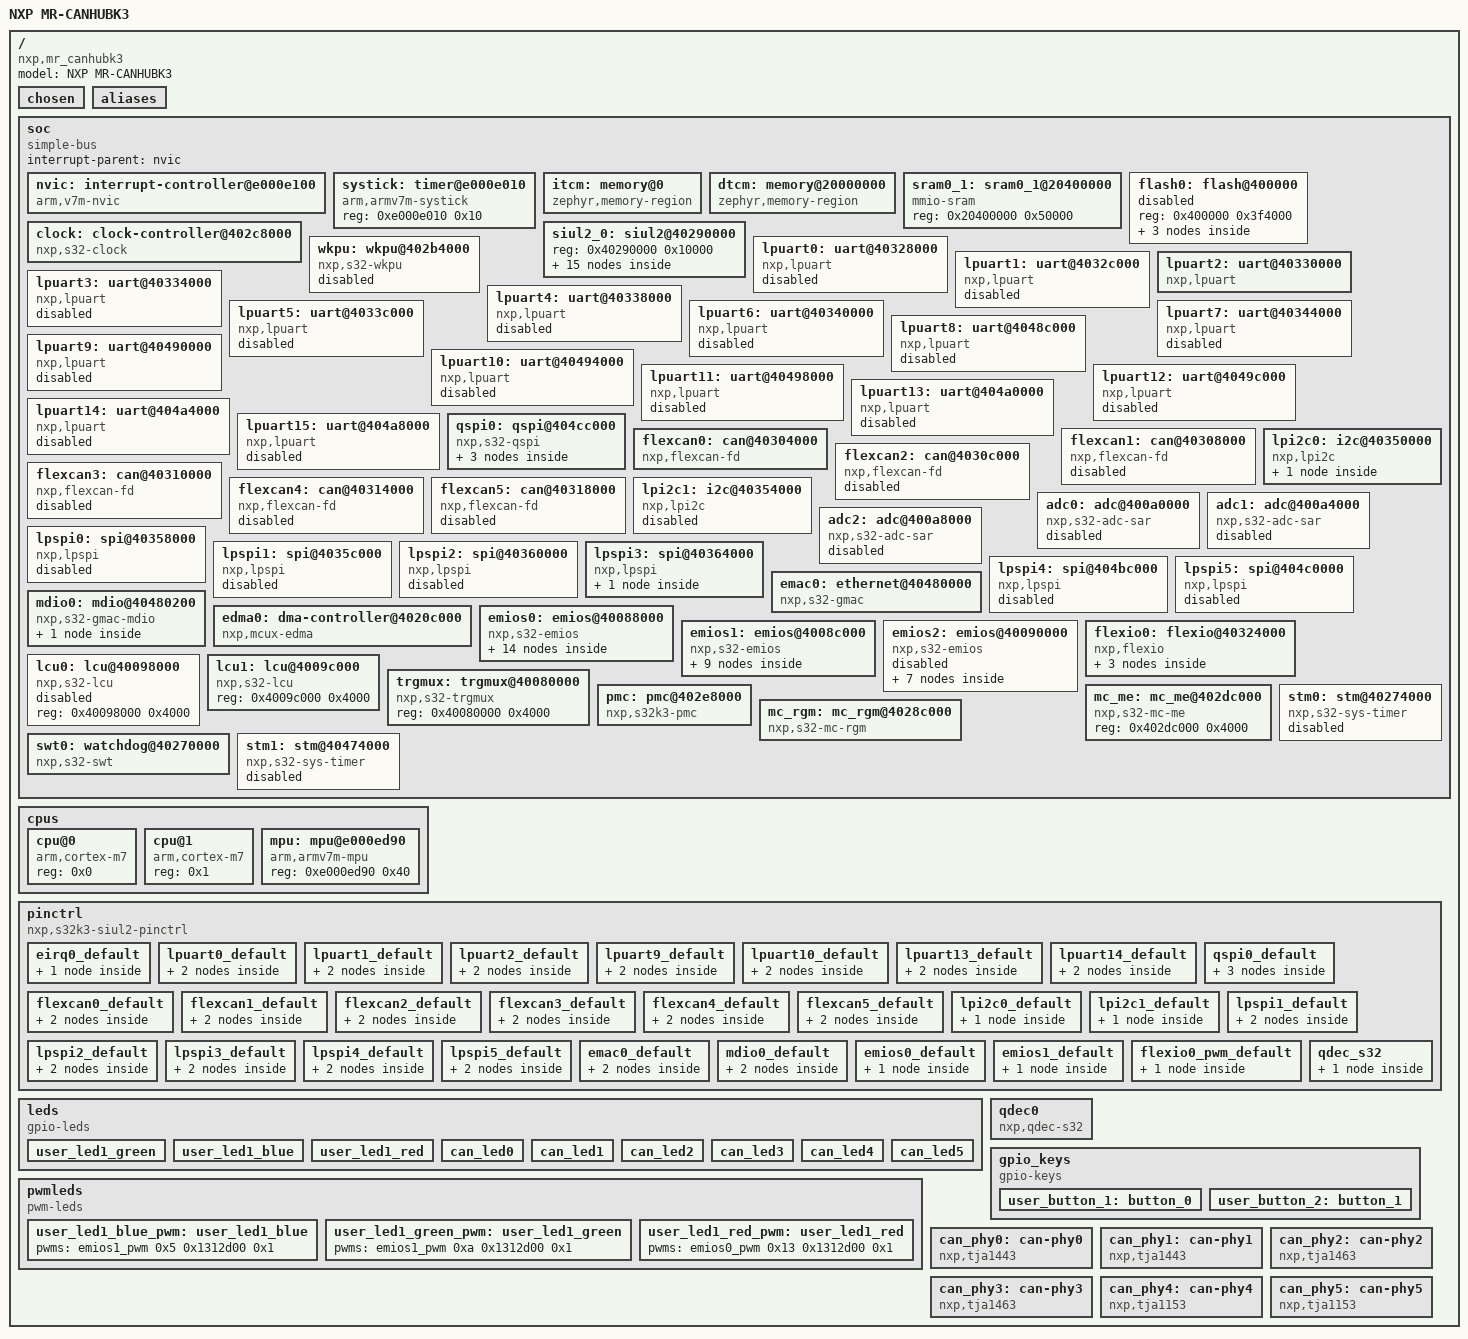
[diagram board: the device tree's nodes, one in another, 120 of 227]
/dts-v1/;

/* node '/' defined in zephyr/dts/common/skeleton.dtsi:9 */
/ {
	#address-cells = < 0x1 >;       /* in zephyr/dts/common/skeleton.dtsi:10 */
	#size-cells = < 0x1 >;          /* in zephyr/dts/common/skeleton.dtsi:11 */
	model = "NXP MR-CANHUBK3";      /* in zephyr/boards/nxp/mr_canhubk3/mr_canhubk3.dts:17 */
	compatible = "nxp,mr_canhubk3"; /* in zephyr/boards/nxp/mr_canhubk3/mr_canhubk3.dts:18 */

	/* node '/chosen' defined in zephyr/dts/common/skeleton.dtsi:13 */
	chosen {
		zephyr,sram = &sram0_1;                  /* in zephyr/boards/nxp/mr_canhubk3/mr_canhubk3.dts:21 */
		zephyr,flash = &flash0;                  /* in zephyr/boards/nxp/mr_canhubk3/mr_canhubk3.dts:22 */
		zephyr,itcm = &itcm;                     /* in zephyr/boards/nxp/mr_canhubk3/mr_canhubk3.dts:23 */
		zephyr,dtcm = &dtcm;                     /* in zephyr/boards/nxp/mr_canhubk3/mr_canhubk3.dts:24 */
		zephyr,code-partition = &code_partition; /* in zephyr/boards/nxp/mr_canhubk3/mr_canhubk3.dts:25 */
		zephyr,console = &lpuart2;               /* in zephyr/boards/nxp/mr_canhubk3/mr_canhubk3.dts:26 */
		zephyr,shell-uart = &lpuart2;            /* in zephyr/boards/nxp/mr_canhubk3/mr_canhubk3.dts:27 */
		zephyr,flash-controller = &mx25l6433f;   /* in zephyr/boards/nxp/mr_canhubk3/mr_canhubk3.dts:28 */
		zephyr,canbus = &flexcan0;               /* in zephyr/boards/nxp/mr_canhubk3/mr_canhubk3.dts:29 */
		zephyr,display = &ssd1306;               /* in zephyr/boards/nxp/mr_canhubk3/mr_canhubk3.dts:30 */
	};

	/* node '/aliases' defined in zephyr/dts/common/skeleton.dtsi:15 */
	aliases {
		dma0 = &edma0;                        /* in zephyr/boards/nxp/mr_canhubk3/mr_canhubk3.dts:34 */
		led0 = &user_led1_red;                /* in zephyr/boards/nxp/mr_canhubk3/mr_canhubk3.dts:35 */
		led1 = &user_led1_green;              /* in zephyr/boards/nxp/mr_canhubk3/mr_canhubk3.dts:36 */
		led2 = &user_led1_blue;               /* in zephyr/boards/nxp/mr_canhubk3/mr_canhubk3.dts:37 */
		sw0 = &user_button_1;                 /* in zephyr/boards/nxp/mr_canhubk3/mr_canhubk3.dts:38 */
		sw1 = &user_button_2;                 /* in zephyr/boards/nxp/mr_canhubk3/mr_canhubk3.dts:39 */
		watchdog0 = &swt0;                    /* in zephyr/boards/nxp/mr_canhubk3/mr_canhubk3.dts:40 */
		pwm-0 = &emios0_pwm;                  /* in zephyr/boards/nxp/mr_canhubk3/mr_canhubk3.dts:42 */
		pwm-1 = &flexio0_pwm;                 /* in zephyr/boards/nxp/mr_canhubk3/mr_canhubk3.dts:43 */
		red-pwm-led = &user_led1_red_pwm;     /* in zephyr/boards/nxp/mr_canhubk3/mr_canhubk3.dts:44 */
		green-pwm-led = &user_led1_green_pwm; /* in zephyr/boards/nxp/mr_canhubk3/mr_canhubk3.dts:45 */
		blue-pwm-led = &user_led1_blue_pwm;   /* in zephyr/boards/nxp/mr_canhubk3/mr_canhubk3.dts:46 */
		pwm-led0 = &user_led1_blue_pwm;       /* in zephyr/boards/nxp/mr_canhubk3/mr_canhubk3.dts:47 */
		qdec0 = &qdec0;                       /* in zephyr/boards/nxp/mr_canhubk3/mr_canhubk3.dts:48 */
	};

	/* node '/soc' defined in zephyr/dts/arm/armv7-m.dtsi:6 */
	soc {
		#address-cells = < 0x1 >;     /* in zephyr/dts/arm/armv7-m.dtsi:7 */
		#size-cells = < 0x1 >;        /* in zephyr/dts/arm/armv7-m.dtsi:8 */
		compatible = "simple-bus";    /* in zephyr/dts/arm/armv7-m.dtsi:9 */
		ranges;                       /* in zephyr/dts/arm/armv7-m.dtsi:11 */
		interrupt-parent = < &nvic >; /* in zephyr/dts/arm/nxp/nxp_s32k344_m7.dtsi:44 */

		/* node '/soc/interrupt-controller@e000e100' defined in zephyr/dts/arm/armv7-m.dtsi:13 */
		nvic: interrupt-controller@e000e100 {
			#address-cells = < 0x1 >;            /* in zephyr/dts/arm/armv7-m.dtsi:14 */
			compatible = "arm,v7m-nvic";         /* in zephyr/dts/arm/armv7-m.dtsi:15 */
			reg = < 0xe000e100 0xc00 >;          /* in zephyr/dts/arm/armv7-m.dtsi:16 */
			interrupt-controller;                /* in zephyr/dts/arm/armv7-m.dtsi:17 */
			#interrupt-cells = < 0x2 >;          /* in zephyr/dts/arm/armv7-m.dtsi:18 */
			arm,num-irq-priority-bits = < 0x4 >; /* in zephyr/dts/arm/nxp/nxp_s32k344_m7.dtsi:924 */
			phandle = < 0x1 >;                   /* in zephyr/dts/arm/nxp/nxp_s32k344_m7.dtsi:44 */
		};

		/* node '/soc/timer@e000e010' defined in zephyr/dts/arm/armv7-m.dtsi:21 */
		systick: timer@e000e010 {
			compatible = "arm,armv7m-systick"; /* in zephyr/dts/arm/armv7-m.dtsi:22 */
			reg = < 0xe000e010 0x10 >;         /* in zephyr/dts/arm/armv7-m.dtsi:23 */
		};

		/* node '/soc/memory@0' defined in zephyr/dts/arm/nxp/nxp_s32k344_m7.dtsi:46 */
		itcm: memory@0 {
			compatible = "zephyr,memory-region",
			             "arm,itcm";             /* in zephyr/dts/arm/nxp/nxp_s32k344_m7.dtsi:47 */
			reg = < 0x0 0x10000 >;               /* in zephyr/dts/arm/nxp/nxp_s32k344_m7.dtsi:48 */
			zephyr,memory-region = "ITCM";       /* in zephyr/dts/arm/nxp/nxp_s32k344_m7.dtsi:49 */
			zephyr,memory-attr = < 0x400000 >;   /* in zephyr/dts/arm/nxp/nxp_s32k344_m7.dtsi:50 */
		};

		/* node '/soc/memory@20000000' defined in zephyr/dts/arm/nxp/nxp_s32k344_m7.dtsi:53 */
		dtcm: memory@20000000 {
			compatible = "zephyr,memory-region",
			             "arm,dtcm";             /* in zephyr/dts/arm/nxp/nxp_s32k344_m7.dtsi:54 */
			reg = < 0x20000000 0x20000 >;        /* in zephyr/dts/arm/nxp/nxp_s32k344_m7.dtsi:55 */
			zephyr,memory-region = "DTCM";       /* in zephyr/dts/arm/nxp/nxp_s32k344_m7.dtsi:56 */
			zephyr,memory-attr = < 0x100000 >;   /* in zephyr/dts/arm/nxp/nxp_s32k344_m7.dtsi:57 */
		};

		/* node '/soc/sram0_1@20400000' defined in zephyr/dts/arm/nxp/nxp_s32k344_m7.dtsi:60 */
		sram0_1: sram0_1@20400000 {
			compatible = "mmio-sram";     /* in zephyr/dts/arm/nxp/nxp_s32k344_m7.dtsi:61 */
			reg = < 0x20400000 0x50000 >; /* in zephyr/dts/arm/nxp/nxp_s32k344_m7.dtsi:62 */
		};

		/* node '/soc/flash@400000' defined in zephyr/dts/arm/nxp/nxp_s32k344_m7.dtsi:72 */
		flash0: flash@400000 {
			reg = < 0x400000 0x3f4000 >; /* in zephyr/dts/arm/nxp/nxp_s32k344_m7.dtsi:73 */
			status = "disabled";         /* in zephyr/dts/arm/nxp/nxp_s32k344_m7.dtsi:74 */

			/* node '/soc/flash@400000/partitions' defined in zephyr/boards/nxp/mr_canhubk3/mr_canhubk3.dts:219 */
			partitions {
				compatible = "fixed-partitions"; /* in zephyr/boards/nxp/mr_canhubk3/mr_canhubk3.dts:220 */
				#address-cells = < 0x1 >;        /* in zephyr/boards/nxp/mr_canhubk3/mr_canhubk3.dts:221 */
				#size-cells = < 0x1 >;           /* in zephyr/boards/nxp/mr_canhubk3/mr_canhubk3.dts:222 */

				/* node '/soc/flash@400000/partitions/partition@0' defined in zephyr/boards/nxp/mr_canhubk3/mr_canhubk3.dts:224 */
				ivt_header: partition@0 {
					label = "ivt-header"; /* in zephyr/boards/nxp/mr_canhubk3/mr_canhubk3.dts:225 */
					reg = < 0x0 0x100 >;  /* in zephyr/boards/nxp/mr_canhubk3/mr_canhubk3.dts:226 */
				};

				/* node '/soc/flash@400000/partitions/partition@100' defined in zephyr/boards/nxp/mr_canhubk3/mr_canhubk3.dts:229 */
				code_partition: partition@100 {
					label = "code-partition"; /* in zephyr/boards/nxp/mr_canhubk3/mr_canhubk3.dts:230 */
					reg = < 0x100 0x3f3f00 >; /* in zephyr/boards/nxp/mr_canhubk3/mr_canhubk3.dts:231 */
				};
			};
		};

		/* node '/soc/clock-controller@402c8000' defined in zephyr/dts/arm/nxp/nxp_s32k344_m7.dtsi:77 */
		clock: clock-controller@402c8000 {
			compatible = "nxp,s32-clock"; /* in zephyr/dts/arm/nxp/nxp_s32k344_m7.dtsi:78 */
			reg = < 0x402c8000 0x4000 >,
			      < 0x402cc000 0x4000 >,
			      < 0x402d0000 0x4000 >,
			      < 0x402d4000 0x4000 >,
			      < 0x402d8000 0x4000 >,
			      < 0x402e0000 0x4000 >;  /* in zephyr/dts/arm/nxp/nxp_s32k344_m7.dtsi:79 */
			#clock-cells = < 0x1 >;       /* in zephyr/dts/arm/nxp/nxp_s32k344_m7.dtsi:85 */
			status = "okay";              /* in zephyr/dts/arm/nxp/nxp_s32k344_m7.dtsi:86 */
			phandle = < 0x5 >;            /* in zephyr/dts/arm/nxp/nxp_s32k344_m7.dtsi:334 */
		};

		/* node '/soc/siul2@40290000' defined in zephyr/dts/arm/nxp/nxp_s32k344_m7.dtsi:89 */
		siul2_0: siul2@40290000 {
			reg = < 0x40290000 0x10000 >; /* in zephyr/dts/arm/nxp/nxp_s32k344_m7.dtsi:90 */
			#address-cells = < 0x1 >;     /* in zephyr/dts/arm/nxp/nxp_s32k344_m7.dtsi:91 */
			#size-cells = < 0x1 >;        /* in zephyr/dts/arm/nxp/nxp_s32k344_m7.dtsi:92 */

			/* node '/soc/siul2@40290000/eirq@40290010' defined in zephyr/dts/arm/nxp/nxp_s32k344_m7.dtsi:94 */
			eirq0: eirq@40290010 {
				compatible = "nxp,siul2-eirq";  /* in zephyr/dts/arm/nxp/nxp_s32k344_m7.dtsi:95 */
				reg = < 0x40290010 0xb4 >;      /* in zephyr/dts/arm/nxp/nxp_s32k344_m7.dtsi:96 */
				#address-cells = < 0x0 >;       /* in zephyr/dts/arm/nxp/nxp_s32k344_m7.dtsi:97 */
				interrupts = < 0x35 0x0 >,
				             < 0x36 0x0 >,
				             < 0x37 0x0 >,
				             < 0x38 0x0 >;      /* in zephyr/dts/arm/nxp/nxp_s32k344_m7.dtsi:98 */
				interrupt-controller;           /* in zephyr/dts/arm/nxp/nxp_s32k344_m7.dtsi:99 */
				#interrupt-cells = < 0x2 >;     /* in zephyr/dts/arm/nxp/nxp_s32k344_m7.dtsi:100 */
				pinctrl-0 = < &eirq0_default >; /* in zephyr/boards/nxp/mr_canhubk3/mr_canhubk3.dts:271 */
				pinctrl-names = "default";      /* in zephyr/boards/nxp/mr_canhubk3/mr_canhubk3.dts:272 */
				status = "okay";                /* in zephyr/boards/nxp/mr_canhubk3/mr_canhubk3.dts:273 */
				phandle = < 0x3 >;              /* in zephyr/dts/arm/nxp/nxp_s32k344_m7.dtsi:108 */
			};

			/* node '/soc/siul2@40290000/gpio@40291702' defined in zephyr/dts/arm/nxp/nxp_s32k344_m7.dtsi:104 */
			gpioa_l: gpio@40291702 {
				compatible = "nxp,siul2-gpio";      /* in zephyr/dts/arm/nxp/nxp_s32k344_m7.dtsi:105 */
				reg = < 0x40291702 0x2 >,
				      < 0x40290240 0x40 >;          /* in zephyr/dts/arm/nxp/nxp_s32k344_m7.dtsi:106 */
				reg-names = "pgpdo",
				            "mscr";                 /* in zephyr/dts/arm/nxp/nxp_s32k344_m7.dtsi:107 */
				interrupt-parent = < &eirq0 >;      /* in zephyr/dts/arm/nxp/nxp_s32k344_m7.dtsi:108 */
				interrupts = < 0x0 0x0 >,
				             < 0x1 0x1 >,
				             < 0x2 0x2 >,
				             < 0x3 0x3 >,
				             < 0x4 0x4 >,
				             < 0x5 0x5 >,
				             < 0x6 0x6 >,
				             < 0x7 0x7 >,
				             < 0x8 0x10 >,
				             < 0x9 0x11 >,
				             < 0xa 0x12 >,
				             < 0xb 0x13 >,
				             < 0xc 0x14 >,
				             < 0xd 0x15 >,
				             < 0xe 0x16 >,
				             < 0xf 0x17 >;          /* in zephyr/dts/arm/nxp/nxp_s32k344_m7.dtsi:109 */
				nxp,wkpu = < &wkpu >;               /* in zephyr/dts/arm/nxp/nxp_s32k344_m7.dtsi:113 */
				nxp,wkpu-interrupts = < 0x1 0x9 >,
				                      < 0x2 0x4 >,
				                      < 0x6 0x13 >,
				                      < 0x8 0x1b >,
				                      < 0x9 0x19 >,
				                      < 0xd 0x8 >,
				                      < 0xf 0x18 >; /* in zephyr/dts/arm/nxp/nxp_s32k344_m7.dtsi:114 */
				gpio-controller;                    /* in zephyr/dts/arm/nxp/nxp_s32k344_m7.dtsi:116 */
				#gpio-cells = < 0x2 >;              /* in zephyr/dts/arm/nxp/nxp_s32k344_m7.dtsi:117 */
				ngpios = < 0x10 >;                  /* in zephyr/dts/arm/nxp/nxp_s32k344_m7.dtsi:118 */
				status = "disabled";                /* in zephyr/dts/arm/nxp/nxp_s32k344_m7.dtsi:119 */
			};

			/* node '/soc/siul2@40290000/gpio@40291700' defined in zephyr/dts/arm/nxp/nxp_s32k344_m7.dtsi:122 */
			gpioa_h: gpio@40291700 {
				compatible = "nxp,siul2-gpio";      /* in zephyr/dts/arm/nxp/nxp_s32k344_m7.dtsi:123 */
				reg = < 0x40291700 0x2 >,
				      < 0x40290280 0x40 >;          /* in zephyr/dts/arm/nxp/nxp_s32k344_m7.dtsi:124 */
				reg-names = "pgpdo",
				            "mscr";                 /* in zephyr/dts/arm/nxp/nxp_s32k344_m7.dtsi:125 */
				interrupt-parent = < &eirq0 >;      /* in zephyr/dts/arm/nxp/nxp_s32k344_m7.dtsi:126 */
				interrupts = < 0x0 0x4 >,
				             < 0x2 0x0 >,
				             < 0x3 0x1 >,
				             < 0x4 0x2 >,
				             < 0x5 0x3 >,
				             < 0x9 0x5 >,
				             < 0xc 0x6 >,
				             < 0xe 0x7 >;           /* in zephyr/dts/arm/nxp/nxp_s32k344_m7.dtsi:127 */
				nxp,wkpu = < &wkpu >;               /* in zephyr/dts/arm/nxp/nxp_s32k344_m7.dtsi:129 */
				nxp,wkpu-interrupts = < 0x0 0x23 >,
				                      < 0x4 0x3f >,
				                      < 0x9 0x26 >,
				                      < 0xa 0x27 >,
				                      < 0xe 0x29 >; /* in zephyr/dts/arm/nxp/nxp_s32k344_m7.dtsi:130 */
				gpio-controller;                    /* in zephyr/dts/arm/nxp/nxp_s32k344_m7.dtsi:132 */
				#gpio-cells = < 0x2 >;              /* in zephyr/dts/arm/nxp/nxp_s32k344_m7.dtsi:133 */
				ngpios = < 0x10 >;                  /* in zephyr/dts/arm/nxp/nxp_s32k344_m7.dtsi:134 */
				status = "okay";                    /* in zephyr/boards/nxp/mr_canhubk3/mr_canhubk3.dts:237 */
				phandle = < 0x20 >;                 /* in zephyr/boards/nxp/mr_canhubk3/mr_canhubk3.dts:462 */
			};

			/* node '/soc/siul2@40290000/gpio@40291706' defined in zephyr/dts/arm/nxp/nxp_s32k344_m7.dtsi:138 */
			gpiob_l: gpio@40291706 {
				compatible = "nxp,siul2-gpio";      /* in zephyr/dts/arm/nxp/nxp_s32k344_m7.dtsi:139 */
				reg = < 0x40291706 0x2 >,
				      < 0x402902c0 0x40 >;          /* in zephyr/dts/arm/nxp/nxp_s32k344_m7.dtsi:140 */
				reg-names = "pgpdo",
				            "mscr";                 /* in zephyr/dts/arm/nxp/nxp_s32k344_m7.dtsi:141 */
				interrupt-parent = < &eirq0 >;      /* in zephyr/dts/arm/nxp/nxp_s32k344_m7.dtsi:142 */
				interrupts = < 0x0 0x8 >,
				             < 0x1 0x9 >,
				             < 0x2 0xa >,
				             < 0x3 0xb >,
				             < 0x4 0xc >,
				             < 0x5 0xd >,
				             < 0x8 0xe >,
				             < 0x9 0xf >,
				             < 0xa 0x18 >,
				             < 0xb 0x19 >,
				             < 0xc 0x1a >,
				             < 0xd 0x1b >,
				             < 0xe 0x1c >,
				             < 0xf 0x1d >;          /* in zephyr/dts/arm/nxp/nxp_s32k344_m7.dtsi:143 */
				nxp,wkpu = < &wkpu >;               /* in zephyr/dts/arm/nxp/nxp_s32k344_m7.dtsi:146 */
				nxp,wkpu-interrupts = < 0x0 0xb >,
				                      < 0x2 0xc >,
				                      < 0x8 0x1d >,
				                      < 0x9 0x15 >,
				                      < 0xb 0x14 >,
				                      < 0xc 0x10 >,
				                      < 0xd 0xf >,
				                      < 0xf 0x25 >; /* in zephyr/dts/arm/nxp/nxp_s32k344_m7.dtsi:147 */
				gpio-controller;                    /* in zephyr/dts/arm/nxp/nxp_s32k344_m7.dtsi:149 */
				#gpio-cells = < 0x2 >;              /* in zephyr/dts/arm/nxp/nxp_s32k344_m7.dtsi:150 */
				ngpios = < 0x10 >;                  /* in zephyr/dts/arm/nxp/nxp_s32k344_m7.dtsi:151 */
				gpio-reserved-ranges = < 0x6 0x2 >; /* in zephyr/dts/arm/nxp/nxp_s32k344_m7.dtsi:152 */
				status = "okay";                    /* in zephyr/boards/nxp/mr_canhubk3/mr_canhubk3.dts:263 */
				phandle = < 0x37 >;                 /* in zephyr/boards/nxp/mr_canhubk3/mr_canhubk3.dts:191 */
			};

			/* node '/soc/siul2@40290000/gpio@40291704' defined in zephyr/dts/arm/nxp/nxp_s32k344_m7.dtsi:156 */
			gpiob_h: gpio@40291704 {
				compatible = "nxp,siul2-gpio";      /* in zephyr/dts/arm/nxp/nxp_s32k344_m7.dtsi:157 */
				reg = < 0x40291704 0x2 >,
				      < 0x40290300 0x40 >;          /* in zephyr/dts/arm/nxp/nxp_s32k344_m7.dtsi:158 */
				reg-names = "pgpdo",
				            "mscr";                 /* in zephyr/dts/arm/nxp/nxp_s32k344_m7.dtsi:159 */
				interrupt-parent = < &eirq0 >;      /* in zephyr/dts/arm/nxp/nxp_s32k344_m7.dtsi:160 */
				interrupts = < 0x0 0x1e >,
				             < 0x1 0x1f >,
				             < 0x5 0x8 >,
				             < 0x6 0x9 >,
				             < 0x7 0xa >,
				             < 0x8 0xb >,
				             < 0x9 0xc >,
				             < 0xa 0xd >,
				             < 0xc 0xe >,
				             < 0xf 0xf >;           /* in zephyr/dts/arm/nxp/nxp_s32k344_m7.dtsi:161 */
				nxp,wkpu = < &wkpu >;               /* in zephyr/dts/arm/nxp/nxp_s32k344_m7.dtsi:163 */
				nxp,wkpu-interrupts = < 0x0 0x11 >,
				                      < 0x1 0x12 >,
				                      < 0x3 0x2a >,
				                      < 0x5 0x2b >,
				                      < 0x7 0x2c >,
				                      < 0xa 0x2d >,
				                      < 0xc 0x2e >; /* in zephyr/dts/arm/nxp/nxp_s32k344_m7.dtsi:164 */
				gpio-controller;                    /* in zephyr/dts/arm/nxp/nxp_s32k344_m7.dtsi:166 */
				#gpio-cells = < 0x2 >;              /* in zephyr/dts/arm/nxp/nxp_s32k344_m7.dtsi:167 */
				ngpios = < 0x10 >;                  /* in zephyr/dts/arm/nxp/nxp_s32k344_m7.dtsi:168 */
				status = "okay";                    /* in zephyr/boards/nxp/mr_canhubk3/mr_canhubk3.dts:247 */
				phandle = < 0x30 >;                 /* in zephyr/boards/nxp/mr_canhubk3/mr_canhubk3.dts:85 */
			};

			/* node '/soc/siul2@40290000/gpio@4029170a' defined in zephyr/dts/arm/nxp/nxp_s32k344_m7.dtsi:172 */
			gpioc_l: gpio@4029170a {
				compatible = "nxp,siul2-gpio";      /* in zephyr/dts/arm/nxp/nxp_s32k344_m7.dtsi:173 */
				reg = < 0x4029170a 0x2 >,
				      < 0x40290340 0x40 >;          /* in zephyr/dts/arm/nxp/nxp_s32k344_m7.dtsi:174 */
				reg-names = "pgpdo",
				            "mscr";                 /* in zephyr/dts/arm/nxp/nxp_s32k344_m7.dtsi:175 */
				interrupt-parent = < &eirq0 >;      /* in zephyr/dts/arm/nxp/nxp_s32k344_m7.dtsi:176 */
				interrupts = < 0x0 0x1 >,
				             < 0x1 0x1 >,
				             < 0x2 0x2 >,
				             < 0x3 0x3 >,
				             < 0x4 0x4 >,
				             < 0x5 0x5 >,
				             < 0x6 0x6 >,
				             < 0x7 0x7 >,
				             < 0x8 0x10 >,
				             < 0x9 0x11 >,
				             < 0xa 0x12 >,
				             < 0xb 0x13 >,
				             < 0xc 0x14 >,
				             < 0xd 0x15 >,
				             < 0xe 0x16 >,
				             < 0xf 0x17 >;          /* in zephyr/dts/arm/nxp/nxp_s32k344_m7.dtsi:177 */
				nxp,wkpu = < &wkpu >;               /* in zephyr/dts/arm/nxp/nxp_s32k344_m7.dtsi:181 */
				nxp,wkpu-interrupts = < 0x6 0x7 >,
				                      < 0x7 0x6 >,
				                      < 0x9 0xe >,
				                      < 0xb 0x16 >; /* in zephyr/dts/arm/nxp/nxp_s32k344_m7.dtsi:182 */
				gpio-controller;                    /* in zephyr/dts/arm/nxp/nxp_s32k344_m7.dtsi:183 */
				#gpio-cells = < 0x2 >;              /* in zephyr/dts/arm/nxp/nxp_s32k344_m7.dtsi:184 */
				ngpios = < 0x10 >;                  /* in zephyr/dts/arm/nxp/nxp_s32k344_m7.dtsi:185 */
				status = "disabled";                /* in zephyr/dts/arm/nxp/nxp_s32k344_m7.dtsi:186 */
			};

			/* node '/soc/siul2@40290000/gpio@40291708' defined in zephyr/dts/arm/nxp/nxp_s32k344_m7.dtsi:189 */
			gpioc_h: gpio@40291708 {
				compatible = "nxp,siul2-gpio";      /* in zephyr/dts/arm/nxp/nxp_s32k344_m7.dtsi:190 */
				reg = < 0x40291708 0x2 >,
				      < 0x40290380 0x40 >;          /* in zephyr/dts/arm/nxp/nxp_s32k344_m7.dtsi:191 */
				reg-names = "pgpdo",
				            "mscr";                 /* in zephyr/dts/arm/nxp/nxp_s32k344_m7.dtsi:192 */
				interrupt-parent = < &eirq0 >;      /* in zephyr/dts/arm/nxp/nxp_s32k344_m7.dtsi:193 */
				interrupts = < 0x4 0x10 >,
				             < 0x5 0x11 >,
				             < 0x7 0x12 >,
				             < 0x8 0x13 >,
				             < 0x9 0x14 >,
				             < 0xa 0x15 >,
				             < 0xb 0x16 >,
				             < 0xd 0x17 >;          /* in zephyr/dts/arm/nxp/nxp_s32k344_m7.dtsi:194 */
				nxp,wkpu = < &wkpu >;               /* in zephyr/dts/arm/nxp/nxp_s32k344_m7.dtsi:196 */
				nxp,wkpu-interrupts = < 0x2 0x28 >,
				                      < 0x4 0x2f >,
				                      < 0x7 0x30 >,
				                      < 0x8 0x32 >,
				                      < 0x9 0x31 >,
				                      < 0xa 0x34 >,
				                      < 0xd 0x33 >,
				                      < 0xf 0x35 >; /* in zephyr/dts/arm/nxp/nxp_s32k344_m7.dtsi:197 */
				gpio-controller;                    /* in zephyr/dts/arm/nxp/nxp_s32k344_m7.dtsi:199 */
				#gpio-cells = < 0x2 >;              /* in zephyr/dts/arm/nxp/nxp_s32k344_m7.dtsi:200 */
				ngpios = < 0x10 >;                  /* in zephyr/dts/arm/nxp/nxp_s32k344_m7.dtsi:201 */
				status = "okay";                    /* in zephyr/boards/nxp/mr_canhubk3/mr_canhubk3.dts:251 */
				phandle = < 0x2e >;                 /* in zephyr/boards/nxp/mr_canhubk3/mr_canhubk3.dts:70 */
			};

			/* node '/soc/siul2@40290000/gpio@4029170e' defined in zephyr/dts/arm/nxp/nxp_s32k344_m7.dtsi:205 */
			gpiod_l: gpio@4029170e {
				compatible = "nxp,siul2-gpio";      /* in zephyr/dts/arm/nxp/nxp_s32k344_m7.dtsi:206 */
				reg = < 0x4029170e 0x2 >,
				      < 0x402903c0 0x40 >;          /* in zephyr/dts/arm/nxp/nxp_s32k344_m7.dtsi:207 */
				reg-names = "pgpdo",
				            "mscr";                 /* in zephyr/dts/arm/nxp/nxp_s32k344_m7.dtsi:208 */
				interrupt-parent = < &eirq0 >;      /* in zephyr/dts/arm/nxp/nxp_s32k344_m7.dtsi:209 */
				interrupts = < 0x0 0x8 >,
				             < 0x1 0x9 >,
				             < 0x2 0xa >,
				             < 0x3 0xb >,
				             < 0x4 0xc >,
				             < 0x5 0xd >,
				             < 0x6 0xe >,
				             < 0x7 0xf >,
				             < 0x8 0x18 >,
				             < 0x9 0x19 >,
				             < 0xa 0x1a >,
				             < 0xb 0x1b >,
				             < 0xc 0x1c >,
				             < 0xd 0x1d >,
				             < 0xe 0x1e >,
				             < 0xf 0x1f >;          /* in zephyr/dts/arm/nxp/nxp_s32k344_m7.dtsi:210 */
				nxp,wkpu = < &wkpu >;               /* in zephyr/dts/arm/nxp/nxp_s32k344_m7.dtsi:214 */
				nxp,wkpu-interrupts = < 0x0 0xa >,
				                      < 0x2 0xd >,
				                      < 0x3 0x5 >,
				                      < 0x4 0x1a >,
				                      < 0xd 0x1c >; /* in zephyr/dts/arm/nxp/nxp_s32k344_m7.dtsi:215 */
				gpio-controller;                    /* in zephyr/dts/arm/nxp/nxp_s32k344_m7.dtsi:217 */
				#gpio-cells = < 0x2 >;              /* in zephyr/dts/arm/nxp/nxp_s32k344_m7.dtsi:218 */
				ngpios = < 0x10 >;                  /* in zephyr/dts/arm/nxp/nxp_s32k344_m7.dtsi:219 */
				status = "okay";                    /* in zephyr/boards/nxp/mr_canhubk3/mr_canhubk3.dts:255 */
				phandle = < 0x26 >;                 /* in zephyr/boards/nxp/mr_canhubk3/mr_canhubk3.dts:497 */
			};

			/* node '/soc/siul2@40290000/gpio@4029170c' defined in zephyr/dts/arm/nxp/nxp_s32k344_m7.dtsi:223 */
			gpiod_h: gpio@4029170c {
				compatible = "nxp,siul2-gpio";      /* in zephyr/dts/arm/nxp/nxp_s32k344_m7.dtsi:224 */
				reg = < 0x4029170c 0x2 >,
				      < 0x40290400 0x40 >;          /* in zephyr/dts/arm/nxp/nxp_s32k344_m7.dtsi:225 */
				reg-names = "pgpdo",
				            "mscr";                 /* in zephyr/dts/arm/nxp/nxp_s32k344_m7.dtsi:226 */
				interrupt-parent = < &eirq0 >;      /* in zephyr/dts/arm/nxp/nxp_s32k344_m7.dtsi:227 */
				interrupts = < 0x1 0x18 >,
				             < 0x4 0x19 >,
				             < 0x5 0x1a >,
				             < 0x6 0x1b >,
				             < 0x7 0x1c >,
				             < 0x8 0x1d >,
				             < 0xb 0x1e >,
				             < 0xc 0x1f >;          /* in zephyr/dts/arm/nxp/nxp_s32k344_m7.dtsi:228 */
				nxp,wkpu = < &wkpu >;               /* in zephyr/dts/arm/nxp/nxp_s32k344_m7.dtsi:230 */
				nxp,wkpu-interrupts = < 0x4 0x3a >,
				                      < 0x7 0x36 >,
				                      < 0xb 0x37 >,
				                      < 0xd 0x38 >,
				                      < 0xf 0x39 >; /* in zephyr/dts/arm/nxp/nxp_s32k344_m7.dtsi:231 */
				gpio-controller;                    /* in zephyr/dts/arm/nxp/nxp_s32k344_m7.dtsi:233 */
				#gpio-cells = < 0x2 >;              /* in zephyr/dts/arm/nxp/nxp_s32k344_m7.dtsi:234 */
				ngpios = < 0x10 >;                  /* in zephyr/dts/arm/nxp/nxp_s32k344_m7.dtsi:235 */
				status = "okay";                    /* in zephyr/boards/nxp/mr_canhubk3/mr_canhubk3.dts:259 */
				phandle = < 0x2f >;                 /* in zephyr/boards/nxp/mr_canhubk3/mr_canhubk3.dts:80 */
			};

			/* node '/soc/siul2@40290000/gpio@40291712' defined in zephyr/dts/arm/nxp/nxp_s32k344_m7.dtsi:239 */
			gpioe_l: gpio@40291712 {
				compatible = "nxp,siul2-gpio";      /* in zephyr/dts/arm/nxp/nxp_s32k344_m7.dtsi:240 */
				reg = < 0x40291712 0x2 >,
				      < 0x40290440 0x40 >;          /* in zephyr/dts/arm/nxp/nxp_s32k344_m7.dtsi:241 */
				reg-names = "pgpdo",
				            "mscr";                 /* in zephyr/dts/arm/nxp/nxp_s32k344_m7.dtsi:242 */
				interrupt-parent = < &eirq0 >;      /* in zephyr/dts/arm/nxp/nxp_s32k344_m7.dtsi:243 */
				interrupts = < 0x0 0x0 >,
				             < 0x1 0x1 >,
				             < 0x2 0x2 >,
				             < 0x3 0x3 >,
				             < 0x4 0x4 >,
				             < 0x5 0x5 >,
				             < 0x6 0x6 >,
				             < 0x8 0x7 >,
				             < 0x9 0x8 >,
				             < 0xa 0x9 >,
				             < 0xb 0xa >,
				             < 0xc 0xb >,
				             < 0xd 0xc >,
				             < 0xe 0xd >,
				             < 0xf 0xe >;           /* in zephyr/dts/arm/nxp/nxp_s32k344_m7.dtsi:244 */
				nxp,wkpu = < &wkpu >;               /* in zephyr/dts/arm/nxp/nxp_s32k344_m7.dtsi:248 */
				nxp,wkpu-interrupts = < 0x0 0x1e >,
				                      < 0x2 0x1f >,
				                      < 0x5 0x24 >,
				                      < 0x6 0x21 >,
				                      < 0xb 0x20 >,
				                      < 0xe 0x22 >; /* in zephyr/dts/arm/nxp/nxp_s32k344_m7.dtsi:249 */
				gpio-controller;                    /* in zephyr/dts/arm/nxp/nxp_s32k344_m7.dtsi:251 */
				#gpio-cells = < 0x2 >;              /* in zephyr/dts/arm/nxp/nxp_s32k344_m7.dtsi:252 */
				ngpios = < 0x10 >;                  /* in zephyr/dts/arm/nxp/nxp_s32k344_m7.dtsi:253 */
				status = "okay";                    /* in zephyr/boards/nxp/mr_canhubk3/mr_canhubk3.dts:241 */
				phandle = < 0x2d >;                 /* in zephyr/boards/nxp/mr_canhubk3/mr_canhubk3.dts:60 */
			};

			/* node '/soc/siul2@40290000/gpio@40291710' defined in zephyr/dts/arm/nxp/nxp_s32k344_m7.dtsi:257 */
			gpioe_h: gpio@40291710 {
				compatible = "nxp,siul2-gpio";      /* in zephyr/dts/arm/nxp/nxp_s32k344_m7.dtsi:258 */
				reg = < 0x40291710 0x2 >,
				      < 0x40290480 0x40 >;          /* in zephyr/dts/arm/nxp/nxp_s32k344_m7.dtsi:259 */
				reg-names = "pgpdo",
				            "mscr";                 /* in zephyr/dts/arm/nxp/nxp_s32k344_m7.dtsi:260 */
				interrupt-parent = < &eirq0 >;      /* in zephyr/dts/arm/nxp/nxp_s32k344_m7.dtsi:261 */
				interrupts = < 0x0 0xf >;           /* in zephyr/dts/arm/nxp/nxp_s32k344_m7.dtsi:262 */
				nxp,wkpu = < &wkpu >;               /* in zephyr/dts/arm/nxp/nxp_s32k344_m7.dtsi:263 */
				nxp,wkpu-interrupts = < 0x0 0x17 >,
				                      < 0x2 0x3b >,
				                      < 0x5 0x3c >,
				                      < 0x7 0x3d >,
				                      < 0x9 0x3e >; /* in zephyr/dts/arm/nxp/nxp_s32k344_m7.dtsi:264 */
				gpio-controller;                    /* in zephyr/dts/arm/nxp/nxp_s32k344_m7.dtsi:266 */
				#gpio-cells = < 0x2 >;              /* in zephyr/dts/arm/nxp/nxp_s32k344_m7.dtsi:267 */
				ngpios = < 0x10 >;                  /* in zephyr/dts/arm/nxp/nxp_s32k344_m7.dtsi:268 */
				status = "okay";                    /* in zephyr/boards/nxp/mr_canhubk3/mr_canhubk3.dts:267 */
				phandle = < 0x38 >;                 /* in zephyr/boards/nxp/mr_canhubk3/mr_canhubk3.dts:207 */
			};

			/* node '/soc/siul2@40290000/gpio@40291716' defined in zephyr/dts/arm/nxp/nxp_s32k344_m7.dtsi:272 */
			gpiof_l: gpio@40291716 {
				compatible = "nxp,siul2-gpio"; /* in zephyr/dts/arm/nxp/nxp_s32k344_m7.dtsi:273 */
				reg = < 0x40291716 0x2 >,
				      < 0x402904c0 0x40 >;     /* in zephyr/dts/arm/nxp/nxp_s32k344_m7.dtsi:274 */
				reg-names = "pgpdo",
				            "mscr";            /* in zephyr/dts/arm/nxp/nxp_s32k344_m7.dtsi:275 */
				interrupt-parent = < &eirq0 >; /* in zephyr/dts/arm/nxp/nxp_s32k344_m7.dtsi:276 */
				interrupts = < 0x0 0x0 >,
				             < 0x1 0x1 >,
				             < 0x2 0x2 >,
				             < 0x3 0x3 >,
				             < 0x4 0x4 >,
				             < 0x5 0x5 >,
				             < 0x6 0x6 >,
				             < 0x7 0x7 >,
				             < 0x8 0x10 >,
				             < 0x9 0x11 >,
				             < 0xa 0x12 >,
				             < 0xb 0x13 >,
				             < 0xc 0x14 >,
				             < 0xd 0x15 >,
				             < 0xe 0x16 >,
				             < 0xf 0x17 >;     /* in zephyr/dts/arm/nxp/nxp_s32k344_m7.dtsi:277 */
				gpio-controller;               /* in zephyr/dts/arm/nxp/nxp_s32k344_m7.dtsi:281 */
				#gpio-cells = < 0x2 >;         /* in zephyr/dts/arm/nxp/nxp_s32k344_m7.dtsi:282 */
				ngpios = < 0x10 >;             /* in zephyr/dts/arm/nxp/nxp_s32k344_m7.dtsi:283 */
				status = "disabled";           /* in zephyr/dts/arm/nxp/nxp_s32k344_m7.dtsi:284 */
			};

			/* node '/soc/siul2@40290000/gpio@40291714' defined in zephyr/dts/arm/nxp/nxp_s32k344_m7.dtsi:287 */
			gpiof_h: gpio@40291714 {
				compatible = "nxp,siul2-gpio"; /* in zephyr/dts/arm/nxp/nxp_s32k344_m7.dtsi:288 */
				reg = < 0x40291714 0x2 >,
				      < 0x40290500 0x40 >;     /* in zephyr/dts/arm/nxp/nxp_s32k344_m7.dtsi:289 */
				reg-names = "pgpdo",
				            "mscr";            /* in zephyr/dts/arm/nxp/nxp_s32k344_m7.dtsi:290 */
				gpio-controller;               /* in zephyr/dts/arm/nxp/nxp_s32k344_m7.dtsi:291 */
				#gpio-cells = < 0x2 >;         /* in zephyr/dts/arm/nxp/nxp_s32k344_m7.dtsi:292 */
				ngpios = < 0x10 >;             /* in zephyr/dts/arm/nxp/nxp_s32k344_m7.dtsi:293 */
				status = "disabled";           /* in zephyr/dts/arm/nxp/nxp_s32k344_m7.dtsi:294 */
			};

			/* node '/soc/siul2@40290000/gpio@4029171a' defined in zephyr/dts/arm/nxp/nxp_s32k344_m7.dtsi:297 */
			gpiog_l: gpio@4029171a {
				compatible = "nxp,siul2-gpio"; /* in zephyr/dts/arm/nxp/nxp_s32k344_m7.dtsi:298 */
				reg = < 0x4029171a 0x2 >,
				      < 0x40290540 0x40 >;     /* in zephyr/dts/arm/nxp/nxp_s32k344_m7.dtsi:299 */
				reg-names = "pgpdo",
				            "mscr";            /* in zephyr/dts/arm/nxp/nxp_s32k344_m7.dtsi:300 */
				interrupt-parent = < &eirq0 >; /* in zephyr/dts/arm/nxp/nxp_s32k344_m7.dtsi:301 */
				interrupts = < 0x0 0x8 >,
				             < 0x1 0x9 >,
				             < 0x2 0xa >,
				             < 0x3 0xb >,
				             < 0x4 0xc >,
				             < 0x5 0xd >,
				             < 0x6 0xe >,
				             < 0x7 0xf >,
				             < 0x8 0x18 >,
				             < 0x9 0x19 >,
				             < 0xa 0x1a >,
				             < 0xb 0x1b >,
				             < 0xc 0x1c >,
				             < 0xd 0x1d >,
				             < 0xe 0x1e >,
				             < 0xf 0x1f >;     /* in zephyr/dts/arm/nxp/nxp_s32k344_m7.dtsi:302 */
				gpio-controller;               /* in zephyr/dts/arm/nxp/nxp_s32k344_m7.dtsi:306 */
				#gpio-cells = < 0x2 >;         /* in zephyr/dts/arm/nxp/nxp_s32k344_m7.dtsi:307 */
				ngpios = < 0x10 >;             /* in zephyr/dts/arm/nxp/nxp_s32k344_m7.dtsi:308 */
				status = "disabled";           /* in zephyr/dts/arm/nxp/nxp_s32k344_m7.dtsi:309 */
			};

			/* node '/soc/siul2@40290000/gpio@40291718' defined in zephyr/dts/arm/nxp/nxp_s32k344_m7.dtsi:312 */
			gpiog_h: gpio@40291718 {
				compatible = "nxp,siul2-gpio"; /* in zephyr/dts/arm/nxp/nxp_s32k344_m7.dtsi:313 */
				reg = < 0x40291718 0x2 >,
				      < 0x40290580 0x40 >;     /* in zephyr/dts/arm/nxp/nxp_s32k344_m7.dtsi:314 */
				reg-names = "pgpdo",
				            "mscr";            /* in zephyr/dts/arm/nxp/nxp_s32k344_m7.dtsi:315 */
				gpio-controller;               /* in zephyr/dts/arm/nxp/nxp_s32k344_m7.dtsi:316 */
				#gpio-cells = < 0x2 >;         /* in zephyr/dts/arm/nxp/nxp_s32k344_m7.dtsi:317 */
				ngpios = < 0x10 >;             /* in zephyr/dts/arm/nxp/nxp_s32k344_m7.dtsi:318 */
				status = "disabled";           /* in zephyr/dts/arm/nxp/nxp_s32k344_m7.dtsi:319 */
			};
		};

		/* node '/soc/wkpu@402b4000' defined in zephyr/dts/arm/nxp/nxp_s32k344_m7.dtsi:323 */
		wkpu: wkpu@402b4000 {
			compatible = "nxp,s32-wkpu"; /* in zephyr/dts/arm/nxp/nxp_s32k344_m7.dtsi:324 */
			reg = < 0x402b4000 0x4000 >; /* in zephyr/dts/arm/nxp/nxp_s32k344_m7.dtsi:325 */
			interrupts = < 0x53 0x0 >;   /* in zephyr/dts/arm/nxp/nxp_s32k344_m7.dtsi:326 */
			status = "disabled";         /* in zephyr/dts/arm/nxp/nxp_s32k344_m7.dtsi:327 */
			phandle = < 0x4 >;           /* in zephyr/dts/arm/nxp/nxp_s32k344_m7.dtsi:113 */
		};

		/* node '/soc/uart@40328000' defined in zephyr/dts/arm/nxp/nxp_s32k344_m7.dtsi:330 */
		lpuart0: uart@40328000 {
			compatible = "nxp,lpuart";        /* in zephyr/dts/arm/nxp/nxp_s32k344_m7.dtsi:331 */
			reg = < 0x40328000 0x4000 >;      /* in zephyr/dts/arm/nxp/nxp_s32k344_m7.dtsi:332 */
			interrupts = < 0x8d 0x0 >;        /* in zephyr/dts/arm/nxp/nxp_s32k344_m7.dtsi:333 */
			clocks = < &clock 0x63 >;         /* in zephyr/dts/arm/nxp/nxp_s32k344_m7.dtsi:334 */
			status = "disabled";              /* in zephyr/dts/arm/nxp/nxp_s32k344_m7.dtsi:335 */
			pinctrl-0 = < &lpuart0_default >; /* in zephyr/boards/nxp/mr_canhubk3/mr_canhubk3.dts:277 */
			pinctrl-names = "default";        /* in zephyr/boards/nxp/mr_canhubk3/mr_canhubk3.dts:278 */
			dmas = < &edma0 0x0 0x25 >,
			       < &edma0 0x1 0x26 >;       /* in zephyr/boards/nxp/mr_canhubk3/mr_canhubk3.dts:279 */
			dma-names = "tx",
			            "rx";                 /* in zephyr/boards/nxp/mr_canhubk3/mr_canhubk3.dts:280 */
		};

		/* node '/soc/uart@4032c000' defined in zephyr/dts/arm/nxp/nxp_s32k344_m7.dtsi:338 */
		lpuart1: uart@4032c000 {
			compatible = "nxp,lpuart";        /* in zephyr/dts/arm/nxp/nxp_s32k344_m7.dtsi:339 */
			reg = < 0x4032c000 0x4000 >;      /* in zephyr/dts/arm/nxp/nxp_s32k344_m7.dtsi:340 */
			interrupts = < 0x8e 0x0 >;        /* in zephyr/dts/arm/nxp/nxp_s32k344_m7.dtsi:341 */
			clocks = < &clock 0x64 >;         /* in zephyr/dts/arm/nxp/nxp_s32k344_m7.dtsi:342 */
			status = "disabled";              /* in zephyr/dts/arm/nxp/nxp_s32k344_m7.dtsi:343 */
			pinctrl-0 = < &lpuart1_default >; /* in zephyr/boards/nxp/mr_canhubk3/mr_canhubk3.dts:284 */
			pinctrl-names = "default";        /* in zephyr/boards/nxp/mr_canhubk3/mr_canhubk3.dts:285 */
			dmas = < &edma0 0x2 0x27 >,
			       < &edma0 0x3 0x28 >;       /* in zephyr/boards/nxp/mr_canhubk3/mr_canhubk3.dts:286 */
			dma-names = "tx",
			            "rx";                 /* in zephyr/boards/nxp/mr_canhubk3/mr_canhubk3.dts:287 */
		};

		/* node '/soc/uart@40330000' defined in zephyr/dts/arm/nxp/nxp_s32k344_m7.dtsi:346 */
		lpuart2: uart@40330000 {
			compatible = "nxp,lpuart";        /* in zephyr/dts/arm/nxp/nxp_s32k344_m7.dtsi:347 */
			reg = < 0x40330000 0x4000 >;      /* in zephyr/dts/arm/nxp/nxp_s32k344_m7.dtsi:348 */
			interrupts = < 0x8f 0x0 >;        /* in zephyr/dts/arm/nxp/nxp_s32k344_m7.dtsi:349 */
			clocks = < &clock 0x65 >;         /* in zephyr/dts/arm/nxp/nxp_s32k344_m7.dtsi:350 */
			pinctrl-0 = < &lpuart2_default >; /* in zephyr/boards/nxp/mr_canhubk3/mr_canhubk3.dts:291 */
			pinctrl-names = "default";        /* in zephyr/boards/nxp/mr_canhubk3/mr_canhubk3.dts:292 */
			current-speed = < 0x1c200 >;      /* in zephyr/boards/nxp/mr_canhubk3/mr_canhubk3.dts:293 */
			dmas = < &edma0 0x10 0x26 >,
			       < &edma0 0x11 0x27 >;      /* in zephyr/boards/nxp/mr_canhubk3/mr_canhubk3.dts:294 */
			dma-names = "tx",
			            "rx";                 /* in zephyr/boards/nxp/mr_canhubk3/mr_canhubk3.dts:295 */
			status = "okay";                  /* in zephyr/boards/nxp/mr_canhubk3/mr_canhubk3.dts:296 */
		};

		/* node '/soc/uart@40334000' defined in zephyr/dts/arm/nxp/nxp_s32k344_m7.dtsi:354 */
		lpuart3: uart@40334000 {
			compatible = "nxp,lpuart";   /* in zephyr/dts/arm/nxp/nxp_s32k344_m7.dtsi:355 */
			reg = < 0x40334000 0x4000 >; /* in zephyr/dts/arm/nxp/nxp_s32k344_m7.dtsi:356 */
			interrupts = < 0x90 0x0 >;   /* in zephyr/dts/arm/nxp/nxp_s32k344_m7.dtsi:357 */
			clocks = < &clock 0x66 >;    /* in zephyr/dts/arm/nxp/nxp_s32k344_m7.dtsi:358 */
			status = "disabled";         /* in zephyr/dts/arm/nxp/nxp_s32k344_m7.dtsi:359 */
		};

		/* node '/soc/uart@40338000' defined in zephyr/dts/arm/nxp/nxp_s32k344_m7.dtsi:362 */
		lpuart4: uart@40338000 {
			compatible = "nxp,lpuart";   /* in zephyr/dts/arm/nxp/nxp_s32k344_m7.dtsi:363 */
			reg = < 0x40338000 0x4000 >; /* in zephyr/dts/arm/nxp/nxp_s32k344_m7.dtsi:364 */
			interrupts = < 0x91 0x0 >;   /* in zephyr/dts/arm/nxp/nxp_s32k344_m7.dtsi:365 */
			clocks = < &clock 0x67 >;    /* in zephyr/dts/arm/nxp/nxp_s32k344_m7.dtsi:366 */
			status = "disabled";         /* in zephyr/dts/arm/nxp/nxp_s32k344_m7.dtsi:367 */
		};

		/* node '/soc/uart@4033c000' defined in zephyr/dts/arm/nxp/nxp_s32k344_m7.dtsi:370 */
		lpuart5: uart@4033c000 {
			compatible = "nxp,lpuart";   /* in zephyr/dts/arm/nxp/nxp_s32k344_m7.dtsi:371 */
			reg = < 0x4033c000 0x4000 >; /* in zephyr/dts/arm/nxp/nxp_s32k344_m7.dtsi:372 */
			interrupts = < 0x92 0x0 >;   /* in zephyr/dts/arm/nxp/nxp_s32k344_m7.dtsi:373 */
			clocks = < &clock 0x68 >;    /* in zephyr/dts/arm/nxp/nxp_s32k344_m7.dtsi:374 */
			status = "disabled";         /* in zephyr/dts/arm/nxp/nxp_s32k344_m7.dtsi:375 */
		};

		/* node '/soc/uart@40340000' defined in zephyr/dts/arm/nxp/nxp_s32k344_m7.dtsi:378 */
		lpuart6: uart@40340000 {
			compatible = "nxp,lpuart";   /* in zephyr/dts/arm/nxp/nxp_s32k344_m7.dtsi:379 */
			reg = < 0x40340000 0x4000 >; /* in zephyr/dts/arm/nxp/nxp_s32k344_m7.dtsi:380 */
			interrupts = < 0x93 0x0 >;   /* in zephyr/dts/arm/nxp/nxp_s32k344_m7.dtsi:381 */
			clocks = < &clock 0x69 >;    /* in zephyr/dts/arm/nxp/nxp_s32k344_m7.dtsi:382 */
			status = "disabled";         /* in zephyr/dts/arm/nxp/nxp_s32k344_m7.dtsi:383 */
		};

		/* node '/soc/uart@40344000' defined in zephyr/dts/arm/nxp/nxp_s32k344_m7.dtsi:386 */
		lpuart7: uart@40344000 {
			compatible = "nxp,lpuart";   /* in zephyr/dts/arm/nxp/nxp_s32k344_m7.dtsi:387 */
			reg = < 0x40344000 0x4000 >; /* in zephyr/dts/arm/nxp/nxp_s32k344_m7.dtsi:388 */
			interrupts = < 0x94 0x0 >;   /* in zephyr/dts/arm/nxp/nxp_s32k344_m7.dtsi:389 */
			clocks = < &clock 0x6a >;    /* in zephyr/dts/arm/nxp/nxp_s32k344_m7.dtsi:390 */
			status = "disabled";         /* in zephyr/dts/arm/nxp/nxp_s32k344_m7.dtsi:391 */
		};

		/* node '/soc/uart@4048c000' defined in zephyr/dts/arm/nxp/nxp_s32k344_m7.dtsi:394 */
		lpuart8: uart@4048c000 {
			compatible = "nxp,lpuart";   /* in zephyr/dts/arm/nxp/nxp_s32k344_m7.dtsi:395 */
			reg = < 0x4048c000 0x4000 >; /* in zephyr/dts/arm/nxp/nxp_s32k344_m7.dtsi:396 */
			interrupts = < 0x95 0x0 >;   /* in zephyr/dts/arm/nxp/nxp_s32k344_m7.dtsi:397 */
			clocks = < &clock 0x6b >;    /* in zephyr/dts/arm/nxp/nxp_s32k344_m7.dtsi:398 */
			status = "disabled";         /* in zephyr/dts/arm/nxp/nxp_s32k344_m7.dtsi:399 */
		};

		/* node '/soc/uart@40490000' defined in zephyr/dts/arm/nxp/nxp_s32k344_m7.dtsi:402 */
		lpuart9: uart@40490000 {
			compatible = "nxp,lpuart";        /* in zephyr/dts/arm/nxp/nxp_s32k344_m7.dtsi:403 */
			reg = < 0x40490000 0x4000 >;      /* in zephyr/dts/arm/nxp/nxp_s32k344_m7.dtsi:404 */
			interrupts = < 0x96 0x0 >;        /* in zephyr/dts/arm/nxp/nxp_s32k344_m7.dtsi:405 */
			clocks = < &clock 0x6c >;         /* in zephyr/dts/arm/nxp/nxp_s32k344_m7.dtsi:406 */
			status = "disabled";              /* in zephyr/dts/arm/nxp/nxp_s32k344_m7.dtsi:407 */
			pinctrl-0 = < &lpuart9_default >; /* in zephyr/boards/nxp/mr_canhubk3/mr_canhubk3.dts:300 */
			pinctrl-names = "default";        /* in zephyr/boards/nxp/mr_canhubk3/mr_canhubk3.dts:301 */
			dmas = < &edma0 0x4 0x27 >,
			       < &edma0 0x5 0x28 >;       /* in zephyr/boards/nxp/mr_canhubk3/mr_canhubk3.dts:307 */
			dma-names = "tx",
			            "rx";                 /* in zephyr/boards/nxp/mr_canhubk3/mr_canhubk3.dts:308 */
		};

		/* node '/soc/uart@40494000' defined in zephyr/dts/arm/nxp/nxp_s32k344_m7.dtsi:410 */
		lpuart10: uart@40494000 {
			compatible = "nxp,lpuart";         /* in zephyr/dts/arm/nxp/nxp_s32k344_m7.dtsi:411 */
			reg = < 0x40494000 0x4000 >;       /* in zephyr/dts/arm/nxp/nxp_s32k344_m7.dtsi:412 */
			interrupts = < 0x97 0x0 >;         /* in zephyr/dts/arm/nxp/nxp_s32k344_m7.dtsi:413 */
			clocks = < &clock 0x6d >;          /* in zephyr/dts/arm/nxp/nxp_s32k344_m7.dtsi:414 */
			status = "disabled";               /* in zephyr/dts/arm/nxp/nxp_s32k344_m7.dtsi:415 */
			pinctrl-0 = < &lpuart10_default >; /* in zephyr/boards/nxp/mr_canhubk3/mr_canhubk3.dts:312 */
			pinctrl-names = "default";         /* in zephyr/boards/nxp/mr_canhubk3/mr_canhubk3.dts:313 */
			dmas = < &edma0 0x12 0x26 >,
			       < &edma0 0x13 0x27 >;       /* in zephyr/boards/nxp/mr_canhubk3/mr_canhubk3.dts:319 */
			dma-names = "tx",
			            "rx";                  /* in zephyr/boards/nxp/mr_canhubk3/mr_canhubk3.dts:320 */
		};

		/* node '/soc/uart@40498000' defined in zephyr/dts/arm/nxp/nxp_s32k344_m7.dtsi:418 */
		lpuart11: uart@40498000 {
			compatible = "nxp,lpuart";   /* in zephyr/dts/arm/nxp/nxp_s32k344_m7.dtsi:419 */
			reg = < 0x40498000 0x4000 >; /* in zephyr/dts/arm/nxp/nxp_s32k344_m7.dtsi:420 */
			interrupts = < 0x98 0x0 >;   /* in zephyr/dts/arm/nxp/nxp_s32k344_m7.dtsi:421 */
			clocks = < &clock 0x6e >;    /* in zephyr/dts/arm/nxp/nxp_s32k344_m7.dtsi:422 */
			status = "disabled";         /* in zephyr/dts/arm/nxp/nxp_s32k344_m7.dtsi:423 */
		};

		/* node '/soc/uart@4049c000' defined in zephyr/dts/arm/nxp/nxp_s32k344_m7.dtsi:426 */
		lpuart12: uart@4049c000 {
			compatible = "nxp,lpuart";   /* in zephyr/dts/arm/nxp/nxp_s32k344_m7.dtsi:427 */
			reg = < 0x4049c000 0x4000 >; /* in zephyr/dts/arm/nxp/nxp_s32k344_m7.dtsi:428 */
			interrupts = < 0x99 0x0 >;   /* in zephyr/dts/arm/nxp/nxp_s32k344_m7.dtsi:429 */
			clocks = < &clock 0x6f >;    /* in zephyr/dts/arm/nxp/nxp_s32k344_m7.dtsi:430 */
			status = "disabled";         /* in zephyr/dts/arm/nxp/nxp_s32k344_m7.dtsi:431 */
		};

		/* node '/soc/uart@404a0000' defined in zephyr/dts/arm/nxp/nxp_s32k344_m7.dtsi:434 */
		lpuart13: uart@404a0000 {
			compatible = "nxp,lpuart";         /* in zephyr/dts/arm/nxp/nxp_s32k344_m7.dtsi:435 */
			reg = < 0x404a0000 0x4000 >;       /* in zephyr/dts/arm/nxp/nxp_s32k344_m7.dtsi:436 */
			interrupts = < 0x9a 0x0 >;         /* in zephyr/dts/arm/nxp/nxp_s32k344_m7.dtsi:437 */
			clocks = < &clock 0x70 >;          /* in zephyr/dts/arm/nxp/nxp_s32k344_m7.dtsi:438 */
			status = "disabled";               /* in zephyr/dts/arm/nxp/nxp_s32k344_m7.dtsi:439 */
			pinctrl-0 = < &lpuart13_default >; /* in zephyr/boards/nxp/mr_canhubk3/mr_canhubk3.dts:324 */
			pinctrl-names = "default";         /* in zephyr/boards/nxp/mr_canhubk3/mr_canhubk3.dts:325 */
			dmas = < &edma0 0x14 0x2c >,
			       < &edma0 0x15 0x2d >;       /* in zephyr/boards/nxp/mr_canhubk3/mr_canhubk3.dts:326 */
			dma-names = "tx",
			            "rx";                  /* in zephyr/boards/nxp/mr_canhubk3/mr_canhubk3.dts:327 */
		};

		/* node '/soc/uart@404a4000' defined in zephyr/dts/arm/nxp/nxp_s32k344_m7.dtsi:442 */
		lpuart14: uart@404a4000 {
			compatible = "nxp,lpuart";         /* in zephyr/dts/arm/nxp/nxp_s32k344_m7.dtsi:443 */
			reg = < 0x404a4000 0x4000 >;       /* in zephyr/dts/arm/nxp/nxp_s32k344_m7.dtsi:444 */
			interrupts = < 0x9b 0x0 >;         /* in zephyr/dts/arm/nxp/nxp_s32k344_m7.dtsi:445 */
			clocks = < &clock 0x71 >;          /* in zephyr/dts/arm/nxp/nxp_s32k344_m7.dtsi:446 */
			status = "disabled";               /* in zephyr/dts/arm/nxp/nxp_s32k344_m7.dtsi:447 */
			pinctrl-0 = < &lpuart14_default >; /* in zephyr/boards/nxp/mr_canhubk3/mr_canhubk3.dts:331 */
			pinctrl-names = "default";         /* in zephyr/boards/nxp/mr_canhubk3/mr_canhubk3.dts:332 */
			dmas = < &edma0 0x16 0x2e >,
			       < &edma0 0x17 0x2f >;       /* in zephyr/boards/nxp/mr_canhubk3/mr_canhubk3.dts:333 */
			dma-names = "tx",
			            "rx";                  /* in zephyr/boards/nxp/mr_canhubk3/mr_canhubk3.dts:334 */
		};

		/* node '/soc/uart@404a8000' defined in zephyr/dts/arm/nxp/nxp_s32k344_m7.dtsi:450 */
		lpuart15: uart@404a8000 {
			compatible = "nxp,lpuart";   /* in zephyr/dts/arm/nxp/nxp_s32k344_m7.dtsi:451 */
			reg = < 0x404a8000 0x4000 >; /* in zephyr/dts/arm/nxp/nxp_s32k344_m7.dtsi:452 */
			interrupts = < 0x9c 0x0 >;   /* in zephyr/dts/arm/nxp/nxp_s32k344_m7.dtsi:453 */
			clocks = < &clock 0x72 >;    /* in zephyr/dts/arm/nxp/nxp_s32k344_m7.dtsi:454 */
			status = "disabled";         /* in zephyr/dts/arm/nxp/nxp_s32k344_m7.dtsi:455 */
		};

		/* node '/soc/qspi@404cc000' defined in zephyr/dts/arm/nxp/nxp_s32k344_m7.dtsi:458 */
		qspi0: qspi@404cc000 {
			compatible = "nxp,s32-qspi";               /* in zephyr/dts/arm/nxp/nxp_s32k344_m7.dtsi:459 */
			reg = < 0x404cc000 0x4000 >;               /* in zephyr/dts/arm/nxp/nxp_s32k344_m7.dtsi:460 */
			#address-cells = < 0x1 >;                  /* in zephyr/dts/arm/nxp/nxp_s32k344_m7.dtsi:461 */
			#size-cells = < 0x0 >;                     /* in zephyr/dts/arm/nxp/nxp_s32k344_m7.dtsi:462 */
			pinctrl-0 = < &qspi0_default >;            /* in zephyr/boards/nxp/mr_canhubk3/mr_canhubk3.dts:338 */
			pinctrl-names = "default";                 /* in zephyr/boards/nxp/mr_canhubk3/mr_canhubk3.dts:339 */
			data-rate = "SDR";                         /* in zephyr/boards/nxp/mr_canhubk3/mr_canhubk3.dts:340 */
			a-rx-clock-source = "LOOPBACK";            /* in zephyr/boards/nxp/mr_canhubk3/mr_canhubk3.dts:341 */
			a-dll-mode = "BYPASSED";                   /* in zephyr/boards/nxp/mr_canhubk3/mr_canhubk3.dts:342 */
			ahb-buffers-masters = < 0x0 0x1 0x2 0x3 >; /* in zephyr/boards/nxp/mr_canhubk3/mr_canhubk3.dts:343 */
			ahb-buffers-sizes = < 0x0 0x0 0x0 0x100 >; /* in zephyr/boards/nxp/mr_canhubk3/mr_canhubk3.dts:344 */
			ahb-buffers-all-masters;                   /* in zephyr/boards/nxp/mr_canhubk3/mr_canhubk3.dts:345 */
			status = "okay";                           /* in zephyr/boards/nxp/mr_canhubk3/mr_canhubk3.dts:346 */

			/* node '/soc/qspi@404cc000/mx25l6433f@0' defined in zephyr/boards/nxp/mr_canhubk3/mr_canhubk3.dts:348 */
			mx25l6433f: mx25l6433f@0 {
				compatible = "nxp,s32-qspi-nor";     /* in zephyr/boards/nxp/mr_canhubk3/mr_canhubk3.dts:349 */
				reg = < 0x0 >;                       /* in zephyr/boards/nxp/mr_canhubk3/mr_canhubk3.dts:350 */
				size = < 0x4000000 >;                /* in zephyr/boards/nxp/mr_canhubk3/mr_canhubk3.dts:351 */
				jedec-id = [ C2 20 17 ];             /* in zephyr/boards/nxp/mr_canhubk3/mr_canhubk3.dts:352 */
				quad-enable-requirements = "S1B6";   /* in zephyr/boards/nxp/mr_canhubk3/mr_canhubk3.dts:353 */
				readoc = "1-4-4";                    /* in zephyr/boards/nxp/mr_canhubk3/mr_canhubk3.dts:354 */
				writeoc = "1-4-4";                   /* in zephyr/boards/nxp/mr_canhubk3/mr_canhubk3.dts:355 */
				has-32k-erase;                       /* in zephyr/boards/nxp/mr_canhubk3/mr_canhubk3.dts:356 */
				max-program-buffer-size = < 0x100 >; /* in zephyr/boards/nxp/mr_canhubk3/mr_canhubk3.dts:357 */
				write-block-size = < 0x1 >;          /* in zephyr/boards/nxp/mr_canhubk3/mr_canhubk3.dts:358 */
				status = "okay";                     /* in zephyr/boards/nxp/mr_canhubk3/mr_canhubk3.dts:359 */

				/* node '/soc/qspi@404cc000/mx25l6433f@0/partitions' defined in zephyr/boards/nxp/mr_canhubk3/mr_canhubk3.dts:361 */
				partitions {
					compatible = "fixed-partitions"; /* in zephyr/boards/nxp/mr_canhubk3/mr_canhubk3.dts:362 */
					#address-cells = < 0x1 >;        /* in zephyr/boards/nxp/mr_canhubk3/mr_canhubk3.dts:363 */
					#size-cells = < 0x1 >;           /* in zephyr/boards/nxp/mr_canhubk3/mr_canhubk3.dts:364 */

					/* node '/soc/qspi@404cc000/mx25l6433f@0/partitions/partition@0' defined in zephyr/boards/nxp/mr_canhubk3/mr_canhubk3.dts:366 */
					storage_partition: partition@0 {
						label = "storage";      /* in zephyr/boards/nxp/mr_canhubk3/mr_canhubk3.dts:367 */
						reg = < 0x0 0x100000 >; /* in zephyr/boards/nxp/mr_canhubk3/mr_canhubk3.dts:368 */
					};
				};
			};
		};

		/* node '/soc/can@40304000' defined in zephyr/dts/arm/nxp/nxp_s32k344_m7.dtsi:466 */
		flexcan0: can@40304000 {
			compatible = "nxp,flexcan-fd",
			             "nxp,flexcan";        /* in zephyr/dts/arm/nxp/nxp_s32k344_m7.dtsi:467 */
			reg = < 0x40304000 0x4000 >;       /* in zephyr/dts/arm/nxp/nxp_s32k344_m7.dtsi:468 */
			clocks = < &clock 0x4f >;          /* in zephyr/dts/arm/nxp/nxp_s32k344_m7.dtsi:469 */
			clk-source = < 0x0 >;              /* in zephyr/dts/arm/nxp/nxp_s32k344_m7.dtsi:470 */
			interrupts = < 0x6d 0x0 >,
			             < 0x6e 0x0 >,
			             < 0x6f 0x0 >,
			             < 0x70 0x0 >;         /* in zephyr/dts/arm/nxp/nxp_s32k344_m7.dtsi:471 */
			interrupt-names = "ored",
			                  "ored_0_31_mb",
			                  "ored_32_63_mb",
			                  "ored_64_95_mb"; /* in zephyr/dts/arm/nxp/nxp_s32k344_m7.dtsi:472 */
			pinctrl-0 = < &flexcan0_default >; /* in zephyr/boards/nxp/mr_canhubk3/mr_canhubk3.dts:375 */
			pinctrl-names = "default";         /* in zephyr/boards/nxp/mr_canhubk3/mr_canhubk3.dts:376 */
			phys = < &can_phy0 >;              /* in zephyr/boards/nxp/mr_canhubk3/mr_canhubk3.dts:377 */
			status = "okay";                   /* in zephyr/boards/nxp/mr_canhubk3/mr_canhubk3.dts:378 */
		};

		/* node '/soc/can@40308000' defined in zephyr/dts/arm/nxp/nxp_s32k344_m7.dtsi:477 */
		flexcan1: can@40308000 {
			compatible = "nxp,flexcan-fd",
			             "nxp,flexcan";        /* in zephyr/dts/arm/nxp/nxp_s32k344_m7.dtsi:478 */
			reg = < 0x40308000 0x4000 >;       /* in zephyr/dts/arm/nxp/nxp_s32k344_m7.dtsi:479 */
			clocks = < &clock 0x4f >;          /* in zephyr/dts/arm/nxp/nxp_s32k344_m7.dtsi:480 */
			clk-source = < 0x0 >;              /* in zephyr/dts/arm/nxp/nxp_s32k344_m7.dtsi:481 */
			interrupts = < 0x71 0x0 >,
			             < 0x72 0x0 >,
			             < 0x73 0x0 >;         /* in zephyr/dts/arm/nxp/nxp_s32k344_m7.dtsi:482 */
			interrupt-names = "ored",
			                  "ored_0_31_mb",
			                  "ored_32_63_mb"; /* in zephyr/dts/arm/nxp/nxp_s32k344_m7.dtsi:483 */
			status = "disabled";               /* in zephyr/dts/arm/nxp/nxp_s32k344_m7.dtsi:484 */
			pinctrl-0 = < &flexcan1_default >; /* in zephyr/boards/nxp/mr_canhubk3/mr_canhubk3.dts:382 */
			pinctrl-names = "default";         /* in zephyr/boards/nxp/mr_canhubk3/mr_canhubk3.dts:383 */
			phys = < &can_phy1 >;              /* in zephyr/boards/nxp/mr_canhubk3/mr_canhubk3.dts:384 */
		};

		/* node '/soc/can@4030c000' defined in zephyr/dts/arm/nxp/nxp_s32k344_m7.dtsi:487 */
		flexcan2: can@4030c000 {
			compatible = "nxp,flexcan-fd",
			             "nxp,flexcan";        /* in zephyr/dts/arm/nxp/nxp_s32k344_m7.dtsi:488 */
			reg = < 0x4030c000 0x4000 >;       /* in zephyr/dts/arm/nxp/nxp_s32k344_m7.dtsi:489 */
			clocks = < &clock 0x4f >;          /* in zephyr/dts/arm/nxp/nxp_s32k344_m7.dtsi:490 */
			clk-source = < 0x0 >;              /* in zephyr/dts/arm/nxp/nxp_s32k344_m7.dtsi:491 */
			interrupts = < 0x74 0x0 >,
			             < 0x75 0x0 >,
			             < 0x76 0x0 >;         /* in zephyr/dts/arm/nxp/nxp_s32k344_m7.dtsi:492 */
			interrupt-names = "ored",
			                  "ored_0_31_mb",
			                  "ored_32_63_mb"; /* in zephyr/dts/arm/nxp/nxp_s32k344_m7.dtsi:493 */
			status = "disabled";               /* in zephyr/dts/arm/nxp/nxp_s32k344_m7.dtsi:494 */
			pinctrl-0 = < &flexcan2_default >; /* in zephyr/boards/nxp/mr_canhubk3/mr_canhubk3.dts:388 */
			pinctrl-names = "default";         /* in zephyr/boards/nxp/mr_canhubk3/mr_canhubk3.dts:389 */
			phys = < &can_phy2 >;              /* in zephyr/boards/nxp/mr_canhubk3/mr_canhubk3.dts:390 */
		};

		/* node '/soc/can@40310000' defined in zephyr/dts/arm/nxp/nxp_s32k344_m7.dtsi:497 */
		flexcan3: can@40310000 {
			compatible = "nxp,flexcan-fd",
			             "nxp,flexcan";        /* in zephyr/dts/arm/nxp/nxp_s32k344_m7.dtsi:498 */
			reg = < 0x40310000 0x4000 >;       /* in zephyr/dts/arm/nxp/nxp_s32k344_m7.dtsi:499 */
			clocks = < &clock 0x53 >;          /* in zephyr/dts/arm/nxp/nxp_s32k344_m7.dtsi:500 */
			clk-source = < 0x0 >;              /* in zephyr/dts/arm/nxp/nxp_s32k344_m7.dtsi:501 */
			interrupts = < 0x77 0x0 >,
			             < 0x78 0x0 >;         /* in zephyr/dts/arm/nxp/nxp_s32k344_m7.dtsi:502 */
			interrupt-names = "ored",
			                  "ored_0_31_mb";  /* in zephyr/dts/arm/nxp/nxp_s32k344_m7.dtsi:503 */
			status = "disabled";               /* in zephyr/dts/arm/nxp/nxp_s32k344_m7.dtsi:504 */
			pinctrl-0 = < &flexcan3_default >; /* in zephyr/boards/nxp/mr_canhubk3/mr_canhubk3.dts:394 */
			pinctrl-names = "default";         /* in zephyr/boards/nxp/mr_canhubk3/mr_canhubk3.dts:395 */
			phys = < &can_phy3 >;              /* in zephyr/boards/nxp/mr_canhubk3/mr_canhubk3.dts:396 */
		};

		/* node '/soc/can@40314000' defined in zephyr/dts/arm/nxp/nxp_s32k344_m7.dtsi:507 */
		flexcan4: can@40314000 {
			compatible = "nxp,flexcan-fd",
			             "nxp,flexcan";        /* in zephyr/dts/arm/nxp/nxp_s32k344_m7.dtsi:508 */
			reg = < 0x40314000 0x4000 >;       /* in zephyr/dts/arm/nxp/nxp_s32k344_m7.dtsi:509 */
			clocks = < &clock 0x53 >;          /* in zephyr/dts/arm/nxp/nxp_s32k344_m7.dtsi:510 */
			clk-source = < 0x0 >;              /* in zephyr/dts/arm/nxp/nxp_s32k344_m7.dtsi:511 */
			interrupts = < 0x79 0x0 >,
			             < 0x7a 0x0 >;         /* in zephyr/dts/arm/nxp/nxp_s32k344_m7.dtsi:512 */
			interrupt-names = "ored",
			                  "ored_0_31_mb";  /* in zephyr/dts/arm/nxp/nxp_s32k344_m7.dtsi:513 */
			status = "disabled";               /* in zephyr/dts/arm/nxp/nxp_s32k344_m7.dtsi:514 */
			pinctrl-0 = < &flexcan4_default >; /* in zephyr/boards/nxp/mr_canhubk3/mr_canhubk3.dts:400 */
			pinctrl-names = "default";         /* in zephyr/boards/nxp/mr_canhubk3/mr_canhubk3.dts:401 */
			phys = < &can_phy4 >;              /* in zephyr/boards/nxp/mr_canhubk3/mr_canhubk3.dts:402 */
		};

		/* node '/soc/can@40318000' defined in zephyr/dts/arm/nxp/nxp_s32k344_m7.dtsi:517 */
		flexcan5: can@40318000 {
			compatible = "nxp,flexcan-fd",
			             "nxp,flexcan";        /* in zephyr/dts/arm/nxp/nxp_s32k344_m7.dtsi:518 */
			reg = < 0x40318000 0x4000 >;       /* in zephyr/dts/arm/nxp/nxp_s32k344_m7.dtsi:519 */
			clocks = < &clock 0x53 >;          /* in zephyr/dts/arm/nxp/nxp_s32k344_m7.dtsi:520 */
			clk-source = < 0x0 >;              /* in zephyr/dts/arm/nxp/nxp_s32k344_m7.dtsi:521 */
			interrupts = < 0x7b 0x0 >,
			             < 0x7c 0x0 >;         /* in zephyr/dts/arm/nxp/nxp_s32k344_m7.dtsi:522 */
			interrupt-names = "ored",
			                  "ored_0_31_mb";  /* in zephyr/dts/arm/nxp/nxp_s32k344_m7.dtsi:523 */
			status = "disabled";               /* in zephyr/dts/arm/nxp/nxp_s32k344_m7.dtsi:524 */
			pinctrl-0 = < &flexcan5_default >; /* in zephyr/boards/nxp/mr_canhubk3/mr_canhubk3.dts:406 */
			pinctrl-names = "default";         /* in zephyr/boards/nxp/mr_canhubk3/mr_canhubk3.dts:407 */
			phys = < &can_phy5 >;              /* in zephyr/boards/nxp/mr_canhubk3/mr_canhubk3.dts:408 */
		};

		/* node '/soc/i2c@40350000' defined in zephyr/dts/arm/nxp/nxp_s32k344_m7.dtsi:527 */
		lpi2c0: i2c@40350000 {
			compatible = "nxp,lpi2c";        /* in zephyr/dts/arm/nxp/nxp_s32k344_m7.dtsi:528 */
			reg = < 0x40350000 0x10000 >;    /* in zephyr/dts/arm/nxp/nxp_s32k344_m7.dtsi:529 */
			clocks = < &clock 0x5b >;        /* in zephyr/dts/arm/nxp/nxp_s32k344_m7.dtsi:530 */
			#address-cells = < 0x1 >;        /* in zephyr/dts/arm/nxp/nxp_s32k344_m7.dtsi:531 */
			#size-cells = < 0x0 >;           /* in zephyr/dts/arm/nxp/nxp_s32k344_m7.dtsi:532 */
			interrupts = < 0xa1 0x0 >;       /* in zephyr/dts/arm/nxp/nxp_s32k344_m7.dtsi:533 */
			pinctrl-0 = < &lpi2c0_default >; /* in zephyr/boards/nxp/mr_canhubk3/mr_canhubk3.dts:412 */
			pinctrl-names = "default";       /* in zephyr/boards/nxp/mr_canhubk3/mr_canhubk3.dts:413 */
			clock-frequency = < 0x186a0 >;   /* in zephyr/boards/nxp/mr_canhubk3/mr_canhubk3.dts:414 */
			status = "okay";                 /* in zephyr/boards/nxp/mr_canhubk3/mr_canhubk3.dts:415 */

			/* node '/soc/i2c@40350000/ssd1306@3c' defined in zephyr/boards/nxp/mr_canhubk3/mr_canhubk3.dts:417 */
			ssd1306: ssd1306@3c {
				compatible = "solomon,ssd1306fb"; /* in zephyr/boards/nxp/mr_canhubk3/mr_canhubk3.dts:418 */
				reg = < 0x3c >;                   /* in zephyr/boards/nxp/mr_canhubk3/mr_canhubk3.dts:419 */
				width = < 0x80 >;                 /* in zephyr/boards/nxp/mr_canhubk3/mr_canhubk3.dts:420 */
				height = < 0x20 >;                /* in zephyr/boards/nxp/mr_canhubk3/mr_canhubk3.dts:421 */
				segment-offset = < 0x0 >;         /* in zephyr/boards/nxp/mr_canhubk3/mr_canhubk3.dts:422 */
				page-offset = < 0x0 >;            /* in zephyr/boards/nxp/mr_canhubk3/mr_canhubk3.dts:423 */
				display-offset = < 0x0 >;         /* in zephyr/boards/nxp/mr_canhubk3/mr_canhubk3.dts:424 */
				multiplex-ratio = < 0x1f >;       /* in zephyr/boards/nxp/mr_canhubk3/mr_canhubk3.dts:425 */
				segment-remap;                    /* in zephyr/boards/nxp/mr_canhubk3/mr_canhubk3.dts:426 */
				com-invdir;                       /* in zephyr/boards/nxp/mr_canhubk3/mr_canhubk3.dts:427 */
				com-sequential;                   /* in zephyr/boards/nxp/mr_canhubk3/mr_canhubk3.dts:428 */
				prechargep = < 0x22 >;            /* in zephyr/boards/nxp/mr_canhubk3/mr_canhubk3.dts:429 */
			};
		};

		/* node '/soc/i2c@40354000' defined in zephyr/dts/arm/nxp/nxp_s32k344_m7.dtsi:537 */
		lpi2c1: i2c@40354000 {
			compatible = "nxp,lpi2c";        /* in zephyr/dts/arm/nxp/nxp_s32k344_m7.dtsi:538 */
			reg = < 0x40354000 0x10000 >;    /* in zephyr/dts/arm/nxp/nxp_s32k344_m7.dtsi:539 */
			clocks = < &clock 0x5c >;        /* in zephyr/dts/arm/nxp/nxp_s32k344_m7.dtsi:540 */
			#address-cells = < 0x1 >;        /* in zephyr/dts/arm/nxp/nxp_s32k344_m7.dtsi:541 */
			#size-cells = < 0x0 >;           /* in zephyr/dts/arm/nxp/nxp_s32k344_m7.dtsi:542 */
			interrupts = < 0xa2 0x0 >;       /* in zephyr/dts/arm/nxp/nxp_s32k344_m7.dtsi:543 */
			status = "disabled";             /* in zephyr/dts/arm/nxp/nxp_s32k344_m7.dtsi:544 */
			pinctrl-0 = < &lpi2c1_default >; /* in zephyr/boards/nxp/mr_canhubk3/mr_canhubk3.dts:434 */
			pinctrl-names = "default";       /* in zephyr/boards/nxp/mr_canhubk3/mr_canhubk3.dts:435 */
			clock-frequency = < 0x186a0 >;   /* in zephyr/boards/nxp/mr_canhubk3/mr_canhubk3.dts:436 */
		};

		/* node '/soc/adc@400a0000' defined in zephyr/dts/arm/nxp/nxp_s32k344_m7.dtsi:547 */
		adc0: adc@400a0000 {
			compatible = "nxp,s32-adc-sar"; /* in zephyr/dts/arm/nxp/nxp_s32k344_m7.dtsi:548 */
			reg = < 0x400a0000 0x1000 >;    /* in zephyr/dts/arm/nxp/nxp_s32k344_m7.dtsi:549 */
			interrupts = < 0xb4 0x0 >;      /* in zephyr/dts/arm/nxp/nxp_s32k344_m7.dtsi:550 */
			#io-channel-cells = < 0x1 >;    /* in zephyr/dts/arm/nxp/nxp_s32k344_m7.dtsi:551 */
			status = "disabled";            /* in zephyr/dts/arm/nxp/nxp_s32k344_m7.dtsi:552 */
		};

		/* node '/soc/adc@400a4000' defined in zephyr/dts/arm/nxp/nxp_s32k344_m7.dtsi:555 */
		adc1: adc@400a4000 {
			compatible = "nxp,s32-adc-sar"; /* in zephyr/dts/arm/nxp/nxp_s32k344_m7.dtsi:556 */
			reg = < 0x400a4000 0x1000 >;    /* in zephyr/dts/arm/nxp/nxp_s32k344_m7.dtsi:557 */
			interrupts = < 0xb5 0x0 >;      /* in zephyr/dts/arm/nxp/nxp_s32k344_m7.dtsi:558 */
			#io-channel-cells = < 0x1 >;    /* in zephyr/dts/arm/nxp/nxp_s32k344_m7.dtsi:559 */
			status = "disabled";            /* in zephyr/dts/arm/nxp/nxp_s32k344_m7.dtsi:560 */
		};

		/* node '/soc/adc@400a8000' defined in zephyr/dts/arm/nxp/nxp_s32k344_m7.dtsi:563 */
		adc2: adc@400a8000 {
			compatible = "nxp,s32-adc-sar"; /* in zephyr/dts/arm/nxp/nxp_s32k344_m7.dtsi:564 */
			reg = < 0x400a8000 0x1000 >;    /* in zephyr/dts/arm/nxp/nxp_s32k344_m7.dtsi:565 */
			interrupts = < 0xb6 0x0 >;      /* in zephyr/dts/arm/nxp/nxp_s32k344_m7.dtsi:566 */
			#io-channel-cells = < 0x1 >;    /* in zephyr/dts/arm/nxp/nxp_s32k344_m7.dtsi:567 */
			status = "disabled";            /* in zephyr/dts/arm/nxp/nxp_s32k344_m7.dtsi:568 */
		};

		/* node '/soc/spi@40358000' defined in zephyr/dts/arm/nxp/nxp_s32k344_m7.dtsi:571 */
		lpspi0: spi@40358000 {
			compatible = "nxp,lpspi";    /* in zephyr/dts/arm/nxp/nxp_s32k344_m7.dtsi:572 */
			reg = < 0x40358000 0x4000 >; /* in zephyr/dts/arm/nxp/nxp_s32k344_m7.dtsi:573 */
			interrupts = < 0xa5 0x0 >;   /* in zephyr/dts/arm/nxp/nxp_s32k344_m7.dtsi:574 */
			clocks = < &clock 0x5d >;    /* in zephyr/dts/arm/nxp/nxp_s32k344_m7.dtsi:575 */
			#address-cells = < 0x1 >;    /* in zephyr/dts/arm/nxp/nxp_s32k344_m7.dtsi:576 */
			#size-cells = < 0x0 >;       /* in zephyr/dts/arm/nxp/nxp_s32k344_m7.dtsi:577 */
			tx-fifo-size = < 0x4 >;      /* in zephyr/dts/arm/nxp/nxp_s32k344_m7.dtsi:578 */
			rx-fifo-size = < 0x4 >;      /* in zephyr/dts/arm/nxp/nxp_s32k344_m7.dtsi:579 */
			status = "disabled";         /* in zephyr/dts/arm/nxp/nxp_s32k344_m7.dtsi:580 */
		};

		/* node '/soc/spi@4035c000' defined in zephyr/dts/arm/nxp/nxp_s32k344_m7.dtsi:583 */
		lpspi1: spi@4035c000 {
			compatible = "nxp,lpspi";           /* in zephyr/dts/arm/nxp/nxp_s32k344_m7.dtsi:584 */
			reg = < 0x4035c000 0x4000 >;        /* in zephyr/dts/arm/nxp/nxp_s32k344_m7.dtsi:585 */
			interrupts = < 0xa6 0x0 >;          /* in zephyr/dts/arm/nxp/nxp_s32k344_m7.dtsi:586 */
			clocks = < &clock 0x5e >;           /* in zephyr/dts/arm/nxp/nxp_s32k344_m7.dtsi:587 */
			#address-cells = < 0x1 >;           /* in zephyr/dts/arm/nxp/nxp_s32k344_m7.dtsi:588 */
			#size-cells = < 0x0 >;              /* in zephyr/dts/arm/nxp/nxp_s32k344_m7.dtsi:589 */
			tx-fifo-size = < 0x4 >;             /* in zephyr/dts/arm/nxp/nxp_s32k344_m7.dtsi:590 */
			rx-fifo-size = < 0x4 >;             /* in zephyr/dts/arm/nxp/nxp_s32k344_m7.dtsi:591 */
			status = "disabled";                /* in zephyr/dts/arm/nxp/nxp_s32k344_m7.dtsi:592 */
			pinctrl-0 = < &lpspi1_default >;    /* in zephyr/boards/nxp/mr_canhubk3/mr_canhubk3.dts:440 */
			pinctrl-names = "default";          /* in zephyr/boards/nxp/mr_canhubk3/mr_canhubk3.dts:441 */
			data-pin-config = "sdo-in,sdi-out"; /* in zephyr/boards/nxp/mr_canhubk3/mr_canhubk3.dts:442 */
		};

		/* node '/soc/spi@40360000' defined in zephyr/dts/arm/nxp/nxp_s32k344_m7.dtsi:595 */
		lpspi2: spi@40360000 {
			compatible = "nxp,lpspi";           /* in zephyr/dts/arm/nxp/nxp_s32k344_m7.dtsi:596 */
			reg = < 0x40360000 0x4000 >;        /* in zephyr/dts/arm/nxp/nxp_s32k344_m7.dtsi:597 */
			interrupts = < 0xa7 0x0 >;          /* in zephyr/dts/arm/nxp/nxp_s32k344_m7.dtsi:598 */
			clocks = < &clock 0x5f >;           /* in zephyr/dts/arm/nxp/nxp_s32k344_m7.dtsi:599 */
			#address-cells = < 0x1 >;           /* in zephyr/dts/arm/nxp/nxp_s32k344_m7.dtsi:600 */
			#size-cells = < 0x0 >;              /* in zephyr/dts/arm/nxp/nxp_s32k344_m7.dtsi:601 */
			tx-fifo-size = < 0x4 >;             /* in zephyr/dts/arm/nxp/nxp_s32k344_m7.dtsi:602 */
			rx-fifo-size = < 0x4 >;             /* in zephyr/dts/arm/nxp/nxp_s32k344_m7.dtsi:603 */
			status = "disabled";                /* in zephyr/dts/arm/nxp/nxp_s32k344_m7.dtsi:604 */
			pinctrl-0 = < &lpspi2_default >;    /* in zephyr/boards/nxp/mr_canhubk3/mr_canhubk3.dts:446 */
			pinctrl-names = "default";          /* in zephyr/boards/nxp/mr_canhubk3/mr_canhubk3.dts:447 */
			data-pin-config = "sdo-in,sdi-out"; /* in zephyr/boards/nxp/mr_canhubk3/mr_canhubk3.dts:448 */
		};

		/* node '/soc/spi@40364000' defined in zephyr/dts/arm/nxp/nxp_s32k344_m7.dtsi:607 */
		lpspi3: spi@40364000 {
			compatible = "nxp,lpspi";           /* in zephyr/dts/arm/nxp/nxp_s32k344_m7.dtsi:608 */
			reg = < 0x40364000 0x4000 >;        /* in zephyr/dts/arm/nxp/nxp_s32k344_m7.dtsi:609 */
			interrupts = < 0xa8 0x0 >;          /* in zephyr/dts/arm/nxp/nxp_s32k344_m7.dtsi:610 */
			clocks = < &clock 0x60 >;           /* in zephyr/dts/arm/nxp/nxp_s32k344_m7.dtsi:611 */
			#address-cells = < 0x1 >;           /* in zephyr/dts/arm/nxp/nxp_s32k344_m7.dtsi:612 */
			#size-cells = < 0x0 >;              /* in zephyr/dts/arm/nxp/nxp_s32k344_m7.dtsi:613 */
			tx-fifo-size = < 0x4 >;             /* in zephyr/dts/arm/nxp/nxp_s32k344_m7.dtsi:614 */
			rx-fifo-size = < 0x4 >;             /* in zephyr/dts/arm/nxp/nxp_s32k344_m7.dtsi:615 */
			pinctrl-0 = < &lpspi3_default >;    /* in zephyr/boards/nxp/mr_canhubk3/mr_canhubk3.dts:452 */
			pinctrl-names = "default";          /* in zephyr/boards/nxp/mr_canhubk3/mr_canhubk3.dts:453 */
			data-pin-config = "sdo-in,sdi-out"; /* in zephyr/boards/nxp/mr_canhubk3/mr_canhubk3.dts:454 */
			status = "okay";                    /* in zephyr/boards/nxp/mr_canhubk3/mr_canhubk3.dts:455 */

			/* node '/soc/spi@40364000/watchdog@0' defined in zephyr/boards/nxp/mr_canhubk3/mr_canhubk3.dts:457 */
			fs26_wdt: watchdog@0 {
				compatible = "nxp,fs26-wdog";     /* in zephyr/boards/nxp/mr_canhubk3/mr_canhubk3.dts:458 */
				reg = < 0x0 >;                    /* in zephyr/boards/nxp/mr_canhubk3/mr_canhubk3.dts:459 */
				spi-max-frequency = < 0x4c4b40 >; /* in zephyr/boards/nxp/mr_canhubk3/mr_canhubk3.dts:460 */
				type = "challenger";              /* in zephyr/boards/nxp/mr_canhubk3/mr_canhubk3.dts:461 */
				int-gpios = < &gpioa_h 0x2 0x1 >; /* in zephyr/boards/nxp/mr_canhubk3/mr_canhubk3.dts:462 */
				status = "okay";                  /* in zephyr/boards/nxp/mr_canhubk3/mr_canhubk3.dts:463 */
			};
		};

		/* node '/soc/spi@404bc000' defined in zephyr/dts/arm/nxp/nxp_s32k344_m7.dtsi:619 */
		lpspi4: spi@404bc000 {
			compatible = "nxp,lpspi";           /* in zephyr/dts/arm/nxp/nxp_s32k344_m7.dtsi:620 */
			reg = < 0x404bc000 0x4000 >;        /* in zephyr/dts/arm/nxp/nxp_s32k344_m7.dtsi:621 */
			interrupts = < 0xa9 0x0 >;          /* in zephyr/dts/arm/nxp/nxp_s32k344_m7.dtsi:622 */
			clocks = < &clock 0x61 >;           /* in zephyr/dts/arm/nxp/nxp_s32k344_m7.dtsi:623 */
			#address-cells = < 0x1 >;           /* in zephyr/dts/arm/nxp/nxp_s32k344_m7.dtsi:624 */
			#size-cells = < 0x0 >;              /* in zephyr/dts/arm/nxp/nxp_s32k344_m7.dtsi:625 */
			tx-fifo-size = < 0x4 >;             /* in zephyr/dts/arm/nxp/nxp_s32k344_m7.dtsi:626 */
			rx-fifo-size = < 0x4 >;             /* in zephyr/dts/arm/nxp/nxp_s32k344_m7.dtsi:627 */
			status = "disabled";                /* in zephyr/dts/arm/nxp/nxp_s32k344_m7.dtsi:628 */
			pinctrl-0 = < &lpspi4_default >;    /* in zephyr/boards/nxp/mr_canhubk3/mr_canhubk3.dts:468 */
			pinctrl-names = "default";          /* in zephyr/boards/nxp/mr_canhubk3/mr_canhubk3.dts:469 */
			data-pin-config = "sdo-in,sdi-out"; /* in zephyr/boards/nxp/mr_canhubk3/mr_canhubk3.dts:470 */
		};

		/* node '/soc/spi@404c0000' defined in zephyr/dts/arm/nxp/nxp_s32k344_m7.dtsi:631 */
		lpspi5: spi@404c0000 {
			compatible = "nxp,lpspi";           /* in zephyr/dts/arm/nxp/nxp_s32k344_m7.dtsi:632 */
			reg = < 0x404c0000 0x4000 >;        /* in zephyr/dts/arm/nxp/nxp_s32k344_m7.dtsi:633 */
			interrupts = < 0xaa 0x0 >;          /* in zephyr/dts/arm/nxp/nxp_s32k344_m7.dtsi:634 */
			clocks = < &clock 0x62 >;           /* in zephyr/dts/arm/nxp/nxp_s32k344_m7.dtsi:635 */
			#address-cells = < 0x1 >;           /* in zephyr/dts/arm/nxp/nxp_s32k344_m7.dtsi:636 */
			#size-cells = < 0x0 >;              /* in zephyr/dts/arm/nxp/nxp_s32k344_m7.dtsi:637 */
			tx-fifo-size = < 0x4 >;             /* in zephyr/dts/arm/nxp/nxp_s32k344_m7.dtsi:638 */
			rx-fifo-size = < 0x4 >;             /* in zephyr/dts/arm/nxp/nxp_s32k344_m7.dtsi:639 */
			status = "disabled";                /* in zephyr/dts/arm/nxp/nxp_s32k344_m7.dtsi:640 */
			pinctrl-0 = < &lpspi5_default >;    /* in zephyr/boards/nxp/mr_canhubk3/mr_canhubk3.dts:474 */
			pinctrl-names = "default";          /* in zephyr/boards/nxp/mr_canhubk3/mr_canhubk3.dts:475 */
			data-pin-config = "sdo-in,sdi-out"; /* in zephyr/boards/nxp/mr_canhubk3/mr_canhubk3.dts:476 */
		};

		/* node '/soc/ethernet@40480000' defined in zephyr/dts/arm/nxp/nxp_s32k344_m7.dtsi:643 */
		emac0: ethernet@40480000 {
			reg = < 0x40480000 0x4000 >;               /* in zephyr/dts/arm/nxp/nxp_s32k344_m7.dtsi:644 */
			compatible = "nxp,s32-gmac";               /* in zephyr/dts/arm/nxp/nxp_s32k344_m7.dtsi:645 */
			interrupts = < 0x69 0x0 >,
			             < 0x6a 0x0 >,
			             < 0x6b 0x0 >,
			             < 0x6c 0x0 >;                 /* in zephyr/dts/arm/nxp/nxp_s32k344_m7.dtsi:646 */
			interrupt-names = "common",
			                  "tx",
			                  "rx",
			                  "safety";                /* in zephyr/dts/arm/nxp/nxp_s32k344_m7.dtsi:647 */
			pinctrl-0 = < &emac0_default >;            /* in zephyr/boards/nxp/mr_canhubk3/mr_canhubk3.dts:480 */
			pinctrl-names = "default";                 /* in zephyr/boards/nxp/mr_canhubk3/mr_canhubk3.dts:481 */
			phy-connection-type = "rmii";              /* in zephyr/boards/nxp/mr_canhubk3/mr_canhubk3.dts:482 */
			local-mac-address = [ 02 04 9F AA BB CC ]; /* in zephyr/boards/nxp/mr_canhubk3/mr_canhubk3.dts:483 */
			phy-handle = < &phy >;                     /* in zephyr/boards/nxp/mr_canhubk3/mr_canhubk3.dts:484 */
			status = "okay";                           /* in zephyr/boards/nxp/mr_canhubk3/mr_canhubk3.dts:485 */
		};

		/* node '/soc/mdio@40480200' defined in zephyr/dts/arm/nxp/nxp_s32k344_m7.dtsi:651 */
		mdio0: mdio@40480200 {
			reg = < 0x40480200 0x8 >;         /* in zephyr/dts/arm/nxp/nxp_s32k344_m7.dtsi:652 */
			compatible = "nxp,s32-gmac-mdio"; /* in zephyr/dts/arm/nxp/nxp_s32k344_m7.dtsi:653 */
			clocks = < &clock 0xf >;          /* in zephyr/dts/arm/nxp/nxp_s32k344_m7.dtsi:654 */
			#address-cells = < 0x1 >;         /* in zephyr/dts/arm/nxp/nxp_s32k344_m7.dtsi:655 */
			#size-cells = < 0x0 >;            /* in zephyr/dts/arm/nxp/nxp_s32k344_m7.dtsi:656 */
			pinctrl-0 = < &mdio0_default >;   /* in zephyr/boards/nxp/mr_canhubk3/mr_canhubk3.dts:489 */
			pinctrl-names = "default";        /* in zephyr/boards/nxp/mr_canhubk3/mr_canhubk3.dts:490 */
			status = "okay";                  /* in zephyr/boards/nxp/mr_canhubk3/mr_canhubk3.dts:491 */

			/* node '/soc/mdio@40480200/ethernet-phy@12' defined in zephyr/boards/nxp/mr_canhubk3/mr_canhubk3.dts:493 */
			phy: ethernet-phy@12 {
				compatible = "nxp,tja1103";       /* in zephyr/boards/nxp/mr_canhubk3/mr_canhubk3.dts:494 */
				status = "okay";                  /* in zephyr/boards/nxp/mr_canhubk3/mr_canhubk3.dts:495 */
				reg = < 0x12 >;                   /* in zephyr/boards/nxp/mr_canhubk3/mr_canhubk3.dts:496 */
				int-gpios = < &gpiod_l 0x5 0x1 >; /* in zephyr/boards/nxp/mr_canhubk3/mr_canhubk3.dts:497 */
				master-slave = "slave";           /* in zephyr/boards/nxp/mr_canhubk3/mr_canhubk3.dts:498 */
				phandle = < 0x24 >;               /* in zephyr/boards/nxp/mr_canhubk3/mr_canhubk3.dts:484 */
			};
		};

		/* node '/soc/dma-controller@4020c000' defined in zephyr/dts/arm/nxp/nxp_s32k344_m7.dtsi:660 */
		edma0: dma-controller@4020c000 {
			compatible = "nxp,mcux-edma"; /* in zephyr/dts/arm/nxp/nxp_s32k344_m7.dtsi:661 */
			nxp,version = < 0x3 >;        /* in zephyr/dts/arm/nxp/nxp_s32k344_m7.dtsi:662 */
			reg = < 0x4020c000 0x3000 >,
			      < 0x40280000 0x4000 >,
			      < 0x40284000 0x4000 >;  /* in zephyr/dts/arm/nxp/nxp_s32k344_m7.dtsi:663 */
			dma-channels = < 0x20 >;      /* in zephyr/dts/arm/nxp/nxp_s32k344_m7.dtsi:664 */
			dma-requests = < 0x40 >;      /* in zephyr/dts/arm/nxp/nxp_s32k344_m7.dtsi:665 */
			dmamux-reg-offset = < 0x3 >;  /* in zephyr/dts/arm/nxp/nxp_s32k344_m7.dtsi:666 */
			channel-gap = < 0xc 0x7f >;   /* in zephyr/dts/arm/nxp/nxp_s32k344_m7.dtsi:667 */
			#dma-cells = < 0x2 >;         /* in zephyr/dts/arm/nxp/nxp_s32k344_m7.dtsi:668 */
			nxp,mem2mem;                  /* in zephyr/dts/arm/nxp/nxp_s32k344_m7.dtsi:669 */
			interrupts = < 0x4 0x0 >,
			             < 0x5 0x0 >,
			             < 0x6 0x0 >,
			             < 0x7 0x0 >,
			             < 0x8 0x0 >,
			             < 0x9 0x0 >,
			             < 0xa 0x0 >,
			             < 0xb 0x0 >,
			             < 0xc 0x0 >,
			             < 0xd 0x0 >,
			             < 0xe 0x0 >,
			             < 0xf 0x0 >,
			             < 0x10 0x0 >,
			             < 0x11 0x0 >,
			             < 0x12 0x0 >,
			             < 0x13 0x0 >,
			             < 0x14 0x0 >,
			             < 0x15 0x0 >,
			             < 0x16 0x0 >,
			             < 0x17 0x0 >,
			             < 0x18 0x0 >,
			             < 0x19 0x0 >,
			             < 0x1a 0x0 >,
			             < 0x1b 0x0 >,
			             < 0x1c 0x0 >,
			             < 0x1d 0x0 >,
			             < 0x1e 0x0 >,
			             < 0x1f 0x0 >,
			             < 0x20 0x0 >,
			             < 0x21 0x0 >,
			             < 0x22 0x0 >,
			             < 0x23 0x0 >;    /* in zephyr/dts/arm/nxp/nxp_s32k344_m7.dtsi:670 */
			no-error-irq;                 /* in zephyr/dts/arm/nxp/nxp_s32k344_m7.dtsi:678 */
			status = "okay";              /* in zephyr/boards/nxp/mr_canhubk3/mr_canhubk3.dts:638 */
			phandle = < 0x7 >;            /* in zephyr/boards/nxp/mr_canhubk3/mr_canhubk3.dts:279 */
		};

		/* node '/soc/emios@40088000' defined in zephyr/dts/arm/nxp/nxp_s32k344_m7.dtsi:682 */
		emios0: emios@40088000 {
			compatible = "nxp,s32-emios"; /* in zephyr/dts/arm/nxp/nxp_s32k344_m7.dtsi:683 */
			reg = < 0x40088000 0x4000 >;  /* in zephyr/dts/arm/nxp/nxp_s32k344_m7.dtsi:684 */
			clocks = < &clock 0x4b >;     /* in zephyr/dts/arm/nxp/nxp_s32k344_m7.dtsi:685 */
			interrupts = < 0x3d 0x0 >,
			             < 0x3e 0x0 >,
			             < 0x3f 0x0 >,
			             < 0x40 0x0 >,
			             < 0x41 0x0 >,
			             < 0x42 0x0 >;    /* in zephyr/dts/arm/nxp/nxp_s32k344_m7.dtsi:686 */
			interrupt-names = "0_0",
			                  "0_1",
			                  "0_2",
			                  "0_3",
			                  "0_4",
			                  "0_5";      /* in zephyr/dts/arm/nxp/nxp_s32k344_m7.dtsi:688 */
			internal-cnt = < 0xc101ff >;  /* in zephyr/dts/arm/nxp/nxp_s32k344_m7.dtsi:690 */
			clock-divider = < 0xc8 >;     /* in zephyr/boards/nxp/mr_canhubk3/mr_canhubk3.dts:503 */
			status = "okay";              /* in zephyr/boards/nxp/mr_canhubk3/mr_canhubk3.dts:504 */
			phandle = < 0x36 >;           /* in zephyr/boards/nxp/mr_canhubk3/mr_canhubk3.dts:141 */

			/* node '/soc/emios@40088000/master_bus' defined in zephyr/dts/arm/nxp/nxp_s32k344_m7.dtsi:693 */
			master_bus {

				/* node '/soc/emios@40088000/master_bus/emios0_bus_a' defined in zephyr/dts/arm/nxp/nxp_s32k344_m7.dtsi:694 */
				emios0_bus_a: emios0_bus_a {
					channel = < 0x17 >;          /* in zephyr/dts/arm/nxp/nxp_s32k344_m7.dtsi:695 */
					bus-type = "BUS_A";          /* in zephyr/dts/arm/nxp/nxp_s32k344_m7.dtsi:696 */
					channel-mask = < 0x7fffff >; /* in zephyr/dts/arm/nxp/nxp_s32k344_m7.dtsi:697 */
					mode = "MCB_UP_COUNTER";     /* in zephyr/boards/nxp/mr_canhubk3/mr_canhubk3.dts:512 */
					prescaler = < 0x10 >;        /* in zephyr/boards/nxp/mr_canhubk3/mr_canhubk3.dts:513 */
					status = "okay";             /* in zephyr/boards/nxp/mr_canhubk3/mr_canhubk3.dts:514 */
					phandle = < 0x28 >;          /* in zephyr/boards/nxp/mr_canhubk3/mr_canhubk3.dts:562 */
				};

				/* node '/soc/emios@40088000/master_bus/emios0_bus_b' defined in zephyr/dts/arm/nxp/nxp_s32k344_m7.dtsi:701 */
				emios0_bus_b: emios0_bus_b {
					channel = < 0x0 >;       /* in zephyr/dts/arm/nxp/nxp_s32k344_m7.dtsi:702 */
					bus-type = "BUS_B";      /* in zephyr/dts/arm/nxp/nxp_s32k344_m7.dtsi:703 */
					channel-mask = < 0xfe >; /* in zephyr/dts/arm/nxp/nxp_s32k344_m7.dtsi:704 */
					status = "disabled";     /* in zephyr/dts/arm/nxp/nxp_s32k344_m7.dtsi:705 */
				};

				/* node '/soc/emios@40088000/master_bus/emios0_bus_c' defined in zephyr/dts/arm/nxp/nxp_s32k344_m7.dtsi:708 */
				emios0_bus_c: emios0_bus_c {
					channel = < 0x8 >;         /* in zephyr/dts/arm/nxp/nxp_s32k344_m7.dtsi:709 */
					bus-type = "BUS_C";        /* in zephyr/dts/arm/nxp/nxp_s32k344_m7.dtsi:710 */
					channel-mask = < 0xfe00 >; /* in zephyr/dts/arm/nxp/nxp_s32k344_m7.dtsi:711 */
					status = "disabled";       /* in zephyr/dts/arm/nxp/nxp_s32k344_m7.dtsi:712 */
				};

				/* node '/soc/emios@40088000/master_bus/emios0_bus_d' defined in zephyr/dts/arm/nxp/nxp_s32k344_m7.dtsi:715 */
				emios0_bus_d: emios0_bus_d {
					channel = < 0x10 >;          /* in zephyr/dts/arm/nxp/nxp_s32k344_m7.dtsi:716 */
					bus-type = "BUS_D";          /* in zephyr/dts/arm/nxp/nxp_s32k344_m7.dtsi:717 */
					channel-mask = < 0xfe0000 >; /* in zephyr/dts/arm/nxp/nxp_s32k344_m7.dtsi:718 */
					status = "disabled";         /* in zephyr/dts/arm/nxp/nxp_s32k344_m7.dtsi:719 */
				};

				/* node '/soc/emios@40088000/master_bus/emios0_bus_f' defined in zephyr/dts/arm/nxp/nxp_s32k344_m7.dtsi:722 */
				emios0_bus_f: emios0_bus_f {
					channel = < 0x16 >;          /* in zephyr/dts/arm/nxp/nxp_s32k344_m7.dtsi:723 */
					bus-type = "BUS_F";          /* in zephyr/dts/arm/nxp/nxp_s32k344_m7.dtsi:724 */
					channel-mask = < 0xbfffff >; /* in zephyr/dts/arm/nxp/nxp_s32k344_m7.dtsi:725 */
					status = "disabled";         /* in zephyr/dts/arm/nxp/nxp_s32k344_m7.dtsi:726 */
				};
			};

			/* node '/soc/emios@40088000/pwm' defined in zephyr/dts/arm/nxp/nxp_s32k344_m7.dtsi:730 */
			emios0_pwm: pwm {
				compatible = "nxp,s32-emios-pwm"; /* in zephyr/dts/arm/nxp/nxp_s32k344_m7.dtsi:731 */
				#pwm-cells = < 0x3 >;             /* in zephyr/dts/arm/nxp/nxp_s32k344_m7.dtsi:732 */
				pinctrl-0 = < &emios0_default >;  /* in zephyr/boards/nxp/mr_canhubk3/mr_canhubk3.dts:519 */
				pinctrl-names = "default";        /* in zephyr/boards/nxp/mr_canhubk3/mr_canhubk3.dts:520 */
				status = "okay";                  /* in zephyr/boards/nxp/mr_canhubk3/mr_canhubk3.dts:521 */
				phandle = < 0x32 >;               /* in zephyr/boards/nxp/mr_canhubk3/mr_canhubk3.dts:113 */

				/* node '/soc/emios@40088000/pwm/pwm_0' defined in zephyr/boards/nxp/mr_canhubk3/mr_canhubk3.dts:524 */
				pwm_0 {
					channel = < 0x0 >;   /* in zephyr/boards/nxp/mr_canhubk3/mr_canhubk3.dts:525 */
					pwm-mode = "OPWFMB"; /* in zephyr/boards/nxp/mr_canhubk3/mr_canhubk3.dts:526 */
					prescaler = < 0x8 >; /* in zephyr/boards/nxp/mr_canhubk3/mr_canhubk3.dts:527 */
				};

				/* node '/soc/emios@40088000/pwm/pwm_1' defined in zephyr/boards/nxp/mr_canhubk3/mr_canhubk3.dts:530 */
				pwm_1 {
					channel = < 0x1 >;   /* in zephyr/boards/nxp/mr_canhubk3/mr_canhubk3.dts:531 */
					pwm-mode = "OPWFMB"; /* in zephyr/boards/nxp/mr_canhubk3/mr_canhubk3.dts:532 */
					prescaler = < 0x8 >; /* in zephyr/boards/nxp/mr_canhubk3/mr_canhubk3.dts:533 */
				};

				/* node '/soc/emios@40088000/pwm/pwm_2' defined in zephyr/boards/nxp/mr_canhubk3/mr_canhubk3.dts:536 */
				pwm_2 {
					channel = < 0x2 >;   /* in zephyr/boards/nxp/mr_canhubk3/mr_canhubk3.dts:537 */
					pwm-mode = "OPWFMB"; /* in zephyr/boards/nxp/mr_canhubk3/mr_canhubk3.dts:538 */
					prescaler = < 0x8 >; /* in zephyr/boards/nxp/mr_canhubk3/mr_canhubk3.dts:539 */
				};

				/* node '/soc/emios@40088000/pwm/pwm_3' defined in zephyr/boards/nxp/mr_canhubk3/mr_canhubk3.dts:542 */
				pwm_3 {
					channel = < 0x3 >;   /* in zephyr/boards/nxp/mr_canhubk3/mr_canhubk3.dts:543 */
					pwm-mode = "OPWFMB"; /* in zephyr/boards/nxp/mr_canhubk3/mr_canhubk3.dts:544 */
					prescaler = < 0x8 >; /* in zephyr/boards/nxp/mr_canhubk3/mr_canhubk3.dts:545 */
				};

				/* node '/soc/emios@40088000/pwm/pwm_4' defined in zephyr/boards/nxp/mr_canhubk3/mr_canhubk3.dts:548 */
				pwm_4 {
					channel = < 0x4 >;   /* in zephyr/boards/nxp/mr_canhubk3/mr_canhubk3.dts:549 */
					pwm-mode = "OPWFMB"; /* in zephyr/boards/nxp/mr_canhubk3/mr_canhubk3.dts:550 */
					prescaler = < 0x8 >; /* in zephyr/boards/nxp/mr_canhubk3/mr_canhubk3.dts:551 */
				};

				/* node '/soc/emios@40088000/pwm/pwm_5' defined in zephyr/boards/nxp/mr_canhubk3/mr_canhubk3.dts:554 */
				pwm_5 {
					channel = < 0x5 >;   /* in zephyr/boards/nxp/mr_canhubk3/mr_canhubk3.dts:555 */
					pwm-mode = "OPWFMB"; /* in zephyr/boards/nxp/mr_canhubk3/mr_canhubk3.dts:556 */
					prescaler = < 0x8 >; /* in zephyr/boards/nxp/mr_canhubk3/mr_canhubk3.dts:557 */
				};

				/* node '/soc/emios@40088000/pwm/rgb_red' defined in zephyr/boards/nxp/mr_canhubk3/mr_canhubk3.dts:560 */
				rgb_red {
					channel = < 0x13 >;             /* in zephyr/boards/nxp/mr_canhubk3/mr_canhubk3.dts:561 */
					master-bus = < &emios0_bus_a >; /* in zephyr/boards/nxp/mr_canhubk3/mr_canhubk3.dts:562 */
					pwm-mode = "OPWMB";             /* in zephyr/boards/nxp/mr_canhubk3/mr_canhubk3.dts:563 */
				};
			};
		};

		/* node '/soc/emios@4008c000' defined in zephyr/dts/arm/nxp/nxp_s32k344_m7.dtsi:737 */
		emios1: emios@4008c000 {
			compatible = "nxp,s32-emios"; /* in zephyr/dts/arm/nxp/nxp_s32k344_m7.dtsi:738 */
			reg = < 0x4008c000 0x4000 >;  /* in zephyr/dts/arm/nxp/nxp_s32k344_m7.dtsi:739 */
			clocks = < &clock 0x4c >;     /* in zephyr/dts/arm/nxp/nxp_s32k344_m7.dtsi:740 */
			interrupts = < 0x45 0x0 >,
			             < 0x46 0x0 >,
			             < 0x47 0x0 >,
			             < 0x48 0x0 >,
			             < 0x49 0x0 >,
			             < 0x4a 0x0 >;    /* in zephyr/dts/arm/nxp/nxp_s32k344_m7.dtsi:741 */
			interrupt-names = "1_0",
			                  "1_1",
			                  "1_2",
			                  "1_3",
			                  "1_4",
			                  "1_5";      /* in zephyr/dts/arm/nxp/nxp_s32k344_m7.dtsi:743 */
			internal-cnt = < 0xc10101 >;  /* in zephyr/dts/arm/nxp/nxp_s32k344_m7.dtsi:745 */
			clock-divider = < 0xc8 >;     /* in zephyr/boards/nxp/mr_canhubk3/mr_canhubk3.dts:569 */
			status = "okay";              /* in zephyr/boards/nxp/mr_canhubk3/mr_canhubk3.dts:570 */

			/* node '/soc/emios@4008c000/master_bus' defined in zephyr/dts/arm/nxp/nxp_s32k344_m7.dtsi:748 */
			master_bus {

				/* node '/soc/emios@4008c000/master_bus/emios1_bus_a' defined in zephyr/dts/arm/nxp/nxp_s32k344_m7.dtsi:749 */
				emios1_bus_a: emios1_bus_a {
					channel = < 0x17 >;          /* in zephyr/dts/arm/nxp/nxp_s32k344_m7.dtsi:750 */
					bus-type = "BUS_A";          /* in zephyr/dts/arm/nxp/nxp_s32k344_m7.dtsi:751 */
					channel-mask = < 0x7fffff >; /* in zephyr/dts/arm/nxp/nxp_s32k344_m7.dtsi:752 */
					prescaler = < 0x10 >;        /* in zephyr/boards/nxp/mr_canhubk3/mr_canhubk3.dts:578 */
					mode = "MCB_UP_COUNTER";     /* in zephyr/boards/nxp/mr_canhubk3/mr_canhubk3.dts:579 */
					status = "okay";             /* in zephyr/boards/nxp/mr_canhubk3/mr_canhubk3.dts:580 */
					phandle = < 0x2a >;          /* in zephyr/boards/nxp/mr_canhubk3/mr_canhubk3.dts:597 */
				};

				/* node '/soc/emios@4008c000/master_bus/emios1_bus_b' defined in zephyr/dts/arm/nxp/nxp_s32k344_m7.dtsi:756 */
				emios1_bus_b: emios1_bus_b {
					channel = < 0x0 >;       /* in zephyr/dts/arm/nxp/nxp_s32k344_m7.dtsi:757 */
					bus-type = "BUS_B";      /* in zephyr/dts/arm/nxp/nxp_s32k344_m7.dtsi:758 */
					channel-mask = < 0xfe >; /* in zephyr/dts/arm/nxp/nxp_s32k344_m7.dtsi:759 */
					status = "disabled";     /* in zephyr/dts/arm/nxp/nxp_s32k344_m7.dtsi:760 */
				};

				/* node '/soc/emios@4008c000/master_bus/emios1_bus_c' defined in zephyr/dts/arm/nxp/nxp_s32k344_m7.dtsi:763 */
				emios1_bus_c: emios1_bus_c {
					channel = < 0x8 >;         /* in zephyr/dts/arm/nxp/nxp_s32k344_m7.dtsi:764 */
					bus-type = "BUS_C";        /* in zephyr/dts/arm/nxp/nxp_s32k344_m7.dtsi:765 */
					channel-mask = < 0xfe00 >; /* in zephyr/dts/arm/nxp/nxp_s32k344_m7.dtsi:766 */
					status = "disabled";       /* in zephyr/dts/arm/nxp/nxp_s32k344_m7.dtsi:767 */
				};

				/* node '/soc/emios@4008c000/master_bus/emios1_bus_d' defined in zephyr/dts/arm/nxp/nxp_s32k344_m7.dtsi:770 */
				emios1_bus_d: emios1_bus_d {
					channel = < 0x10 >;          /* in zephyr/dts/arm/nxp/nxp_s32k344_m7.dtsi:771 */
					bus-type = "BUS_D";          /* in zephyr/dts/arm/nxp/nxp_s32k344_m7.dtsi:772 */
					channel-mask = < 0xfe0000 >; /* in zephyr/dts/arm/nxp/nxp_s32k344_m7.dtsi:773 */
					status = "disabled";         /* in zephyr/dts/arm/nxp/nxp_s32k344_m7.dtsi:774 */
				};

				/* node '/soc/emios@4008c000/master_bus/emios1_bus_f' defined in zephyr/dts/arm/nxp/nxp_s32k344_m7.dtsi:777 */
				emios1_bus_f: emios1_bus_f {
					channel = < 0x16 >;          /* in zephyr/dts/arm/nxp/nxp_s32k344_m7.dtsi:778 */
					channel-mask = < 0xbfffff >; /* in zephyr/dts/arm/nxp/nxp_s32k344_m7.dtsi:779 */
					bus-type = "BUS_F";          /* in zephyr/dts/arm/nxp/nxp_s32k344_m7.dtsi:780 */
					prescaler = < 0x10 >;        /* in zephyr/boards/nxp/mr_canhubk3/mr_canhubk3.dts:584 */
					mode = "MCB_UP_COUNTER";     /* in zephyr/boards/nxp/mr_canhubk3/mr_canhubk3.dts:585 */
					status = "okay";             /* in zephyr/boards/nxp/mr_canhubk3/mr_canhubk3.dts:586 */
					phandle = < 0x2b >;          /* in zephyr/boards/nxp/mr_canhubk3/mr_canhubk3.dts:603 */
				};
			};

			/* node '/soc/emios@4008c000/pwm' defined in zephyr/dts/arm/nxp/nxp_s32k344_m7.dtsi:785 */
			emios1_pwm: pwm {
				compatible = "nxp,s32-emios-pwm"; /* in zephyr/dts/arm/nxp/nxp_s32k344_m7.dtsi:786 */
				#pwm-cells = < 0x3 >;             /* in zephyr/dts/arm/nxp/nxp_s32k344_m7.dtsi:787 */
				pinctrl-0 = < &emios1_default >;  /* in zephyr/boards/nxp/mr_canhubk3/mr_canhubk3.dts:591 */
				pinctrl-names = "default";        /* in zephyr/boards/nxp/mr_canhubk3/mr_canhubk3.dts:592 */
				status = "okay";                  /* in zephyr/boards/nxp/mr_canhubk3/mr_canhubk3.dts:593 */
				phandle = < 0x31 >;               /* in zephyr/boards/nxp/mr_canhubk3/mr_canhubk3.dts:105 */

				/* node '/soc/emios@4008c000/pwm/rgb_green' defined in zephyr/boards/nxp/mr_canhubk3/mr_canhubk3.dts:595 */
				rgb_green {
					channel = < 0xa >;              /* in zephyr/boards/nxp/mr_canhubk3/mr_canhubk3.dts:596 */
					master-bus = < &emios1_bus_a >; /* in zephyr/boards/nxp/mr_canhubk3/mr_canhubk3.dts:597 */
					pwm-mode = "OPWMB";             /* in zephyr/boards/nxp/mr_canhubk3/mr_canhubk3.dts:598 */
				};

				/* node '/soc/emios@4008c000/pwm/rgb_blue' defined in zephyr/boards/nxp/mr_canhubk3/mr_canhubk3.dts:601 */
				rgb_blue {
					channel = < 0x5 >;              /* in zephyr/boards/nxp/mr_canhubk3/mr_canhubk3.dts:602 */
					master-bus = < &emios1_bus_f >; /* in zephyr/boards/nxp/mr_canhubk3/mr_canhubk3.dts:603 */
					pwm-mode = "OPWMB";             /* in zephyr/boards/nxp/mr_canhubk3/mr_canhubk3.dts:604 */
				};
			};
		};

		/* node '/soc/emios@40090000' defined in zephyr/dts/arm/nxp/nxp_s32k344_m7.dtsi:792 */
		emios2: emios@40090000 {
			compatible = "nxp,s32-emios"; /* in zephyr/dts/arm/nxp/nxp_s32k344_m7.dtsi:793 */
			reg = < 0x40090000 0x4000 >;  /* in zephyr/dts/arm/nxp/nxp_s32k344_m7.dtsi:794 */
			clocks = < &clock 0x4d >;     /* in zephyr/dts/arm/nxp/nxp_s32k344_m7.dtsi:795 */
			interrupts = < 0x4d 0x0 >,
			             < 0x4e 0x0 >,
			             < 0x4f 0x0 >,
			             < 0x50 0x0 >,
			             < 0x51 0x0 >,
			             < 0x52 0x0 >;    /* in zephyr/dts/arm/nxp/nxp_s32k344_m7.dtsi:796 */
			interrupt-names = "2_0",
			                  "2_1",
			                  "2_2",
			                  "2_3",
			                  "2_4",
			                  "2_5";      /* in zephyr/dts/arm/nxp/nxp_s32k344_m7.dtsi:798 */
			internal-cnt = < 0xc10101 >;  /* in zephyr/dts/arm/nxp/nxp_s32k344_m7.dtsi:800 */
			status = "disabled";          /* in zephyr/dts/arm/nxp/nxp_s32k344_m7.dtsi:801 */

			/* node '/soc/emios@40090000/master_bus' defined in zephyr/dts/arm/nxp/nxp_s32k344_m7.dtsi:803 */
			master_bus {

				/* node '/soc/emios@40090000/master_bus/emios2_bus_a' defined in zephyr/dts/arm/nxp/nxp_s32k344_m7.dtsi:804 */
				emios2_bus_a: emios2_bus_a {
					channel = < 0x17 >;          /* in zephyr/dts/arm/nxp/nxp_s32k344_m7.dtsi:805 */
					bus-type = "BUS_A";          /* in zephyr/dts/arm/nxp/nxp_s32k344_m7.dtsi:806 */
					channel-mask = < 0x7fffff >; /* in zephyr/dts/arm/nxp/nxp_s32k344_m7.dtsi:807 */
					status = "disabled";         /* in zephyr/dts/arm/nxp/nxp_s32k344_m7.dtsi:808 */
				};

				/* node '/soc/emios@40090000/master_bus/emios2_bus_b' defined in zephyr/dts/arm/nxp/nxp_s32k344_m7.dtsi:811 */
				emios2_bus_b: emios2_bus_b {
					channel = < 0x0 >;       /* in zephyr/dts/arm/nxp/nxp_s32k344_m7.dtsi:812 */
					bus-type = "BUS_B";      /* in zephyr/dts/arm/nxp/nxp_s32k344_m7.dtsi:813 */
					channel-mask = < 0xfe >; /* in zephyr/dts/arm/nxp/nxp_s32k344_m7.dtsi:814 */
					status = "disabled";     /* in zephyr/dts/arm/nxp/nxp_s32k344_m7.dtsi:815 */
				};

				/* node '/soc/emios@40090000/master_bus/emios2_bus_c' defined in zephyr/dts/arm/nxp/nxp_s32k344_m7.dtsi:818 */
				emios2_bus_c: emios2_bus_c {
					channel = < 0x8 >;         /* in zephyr/dts/arm/nxp/nxp_s32k344_m7.dtsi:819 */
					bus-type = "BUS_C";        /* in zephyr/dts/arm/nxp/nxp_s32k344_m7.dtsi:820 */
					channel-mask = < 0xfe00 >; /* in zephyr/dts/arm/nxp/nxp_s32k344_m7.dtsi:821 */
					status = "disabled";       /* in zephyr/dts/arm/nxp/nxp_s32k344_m7.dtsi:822 */
				};

				/* node '/soc/emios@40090000/master_bus/emios2_bus_d' defined in zephyr/dts/arm/nxp/nxp_s32k344_m7.dtsi:825 */
				emios2_bus_d: emios2_bus_d {
					channel = < 0x10 >;          /* in zephyr/dts/arm/nxp/nxp_s32k344_m7.dtsi:826 */
					bus-type = "BUS_D";          /* in zephyr/dts/arm/nxp/nxp_s32k344_m7.dtsi:827 */
					channel-mask = < 0xfe0000 >; /* in zephyr/dts/arm/nxp/nxp_s32k344_m7.dtsi:828 */
					status = "disabled";         /* in zephyr/dts/arm/nxp/nxp_s32k344_m7.dtsi:829 */
				};

				/* node '/soc/emios@40090000/master_bus/emios2_bus_f' defined in zephyr/dts/arm/nxp/nxp_s32k344_m7.dtsi:832 */
				emios2_bus_f: emios2_bus_f {
					channel = < 0x16 >;          /* in zephyr/dts/arm/nxp/nxp_s32k344_m7.dtsi:833 */
					bus-type = "BUS_F";          /* in zephyr/dts/arm/nxp/nxp_s32k344_m7.dtsi:834 */
					channel-mask = < 0xbfffff >; /* in zephyr/dts/arm/nxp/nxp_s32k344_m7.dtsi:835 */
					status = "disabled";         /* in zephyr/dts/arm/nxp/nxp_s32k344_m7.dtsi:836 */
				};
			};

			/* node '/soc/emios@40090000/pwm' defined in zephyr/dts/arm/nxp/nxp_s32k344_m7.dtsi:840 */
			pwm {
				compatible = "nxp,s32-emios-pwm"; /* in zephyr/dts/arm/nxp/nxp_s32k344_m7.dtsi:841 */
				#pwm-cells = < 0x3 >;             /* in zephyr/dts/arm/nxp/nxp_s32k344_m7.dtsi:842 */
				status = "disabled";              /* in zephyr/dts/arm/nxp/nxp_s32k344_m7.dtsi:843 */
			};
		};

		/* node '/soc/flexio@40324000' defined in zephyr/dts/arm/nxp/nxp_s32k344_m7.dtsi:847 */
		flexio0: flexio@40324000 {
			compatible = "nxp,flexio";   /* in zephyr/dts/arm/nxp/nxp_s32k344_m7.dtsi:848 */
			reg = < 0x40324000 0x4000 >; /* in zephyr/dts/arm/nxp/nxp_s32k344_m7.dtsi:849 */
			interrupts = < 0x8b 0x0 >;   /* in zephyr/dts/arm/nxp/nxp_s32k344_m7.dtsi:850 */
			clocks = < &clock 0x57 >;    /* in zephyr/dts/arm/nxp/nxp_s32k344_m7.dtsi:851 */
			status = "okay";             /* in zephyr/boards/nxp/mr_canhubk3/mr_canhubk3.dts:610 */

			/* node '/soc/flexio@40324000/flexio0_pwm' defined in zephyr/dts/arm/nxp/nxp_s32k344_m7.dtsi:854 */
			flexio0_pwm: flexio0_pwm {
				compatible = "nxp,flexio-pwm";        /* in zephyr/dts/arm/nxp/nxp_s32k344_m7.dtsi:855 */
				#pwm-cells = < 0x3 >;                 /* in zephyr/dts/arm/nxp/nxp_s32k344_m7.dtsi:856 */
				pinctrl-0 = < &flexio0_pwm_default >; /* in zephyr/boards/nxp/mr_canhubk3/mr_canhubk3.dts:613 */
				pinctrl-names = "default";            /* in zephyr/boards/nxp/mr_canhubk3/mr_canhubk3.dts:614 */
				status = "okay";                      /* in zephyr/boards/nxp/mr_canhubk3/mr_canhubk3.dts:615 */

				/* node '/soc/flexio@40324000/flexio0_pwm/pwm_0' defined in zephyr/boards/nxp/mr_canhubk3/mr_canhubk3.dts:617 */
				pwm_0 {
					pin-id = < 0x13 >;   /* in zephyr/boards/nxp/mr_canhubk3/mr_canhubk3.dts:618 */
					prescaler = < 0x1 >; /* in zephyr/boards/nxp/mr_canhubk3/mr_canhubk3.dts:619 */
				};

				/* node '/soc/flexio@40324000/flexio0_pwm/pwm_1' defined in zephyr/boards/nxp/mr_canhubk3/mr_canhubk3.dts:622 */
				pwm_1 {
					pin-id = < 0xb >;    /* in zephyr/boards/nxp/mr_canhubk3/mr_canhubk3.dts:623 */
					prescaler = < 0x1 >; /* in zephyr/boards/nxp/mr_canhubk3/mr_canhubk3.dts:624 */
				};
			};
		};

		/* node '/soc/lcu@40098000' defined in zephyr/dts/arm/nxp/nxp_s32k344_m7.dtsi:861 */
		lcu0: lcu@40098000 {
			compatible = "nxp,s32-lcu";  /* in zephyr/dts/arm/nxp/nxp_s32k344_m7.dtsi:862 */
			reg = < 0x40098000 0x4000 >; /* in zephyr/dts/arm/nxp/nxp_s32k344_m7.dtsi:863 */
			status = "disabled";         /* in zephyr/dts/arm/nxp/nxp_s32k344_m7.dtsi:864 */
		};

		/* node '/soc/lcu@4009c000' defined in zephyr/dts/arm/nxp/nxp_s32k344_m7.dtsi:867 */
		lcu1: lcu@4009c000 {
			compatible = "nxp,s32-lcu";  /* in zephyr/dts/arm/nxp/nxp_s32k344_m7.dtsi:868 */
			reg = < 0x4009c000 0x4000 >; /* in zephyr/dts/arm/nxp/nxp_s32k344_m7.dtsi:869 */
			status = "okay";             /* in zephyr/boards/nxp/mr_canhubk3/mr_canhubk3.dts:630 */
			phandle = < 0x35 >;          /* in zephyr/boards/nxp/mr_canhubk3/mr_canhubk3.dts:130 */
		};

		/* node '/soc/trgmux@40080000' defined in zephyr/dts/arm/nxp/nxp_s32k344_m7.dtsi:873 */
		trgmux: trgmux@40080000 {
			compatible = "nxp,s32-trgmux"; /* in zephyr/dts/arm/nxp/nxp_s32k344_m7.dtsi:874 */
			reg = < 0x40080000 0x4000 >;   /* in zephyr/dts/arm/nxp/nxp_s32k344_m7.dtsi:875 */
			status = "okay";               /* in zephyr/boards/nxp/mr_canhubk3/mr_canhubk3.dts:634 */
			phandle = < 0x34 >;            /* in zephyr/boards/nxp/mr_canhubk3/mr_canhubk3.dts:123 */
		};

		/* node '/soc/pmc@402e8000' defined in zephyr/dts/arm/nxp/nxp_s32k344_m7.dtsi:879 */
		pmc: pmc@402e8000 {
			compatible = "nxp,s32k3-pmc"; /* in zephyr/dts/arm/nxp/nxp_s32k344_m7.dtsi:880 */
			reg = < 0x402e8000 0x4000 >;  /* in zephyr/dts/arm/nxp/nxp_s32k344_m7.dtsi:881 */
			lm-reg;                       /* in zephyr/boards/nxp/mr_canhubk3/mr_canhubk3.dts:215 */
		};

		/* node '/soc/mc_me@402dc000' defined in zephyr/dts/arm/nxp/nxp_s32k344_m7.dtsi:884 */
		mc_me: mc_me@402dc000 {
			compatible = "nxp,s32-mc-me"; /* in zephyr/dts/arm/nxp/nxp_s32k344_m7.dtsi:885 */
			reg = < 0x402dc000 0x4000 >;  /* in zephyr/dts/arm/nxp/nxp_s32k344_m7.dtsi:886 */
		};

		/* node '/soc/mc_rgm@4028c000' defined in zephyr/dts/arm/nxp/nxp_s32k344_m7.dtsi:889 */
		mc_rgm: mc_rgm@4028c000 {
			compatible = "nxp,s32-mc-rgm";  /* in zephyr/dts/arm/nxp/nxp_s32k344_m7.dtsi:890 */
			reg = < 0x4028c000 0x4000 >;    /* in zephyr/dts/arm/nxp/nxp_s32k344_m7.dtsi:891 */
			func-reset-threshold = < 0x0 >; /* in zephyr/dts/arm/nxp/nxp_s32k344_m7.dtsi:892 */
			dest-reset-threshold = < 0x0 >; /* in zephyr/dts/arm/nxp/nxp_s32k344_m7.dtsi:893 */
		};

		/* node '/soc/watchdog@40270000' defined in zephyr/dts/arm/nxp/nxp_s32k344_m7.dtsi:896 */
		swt0: watchdog@40270000 {
			compatible = "nxp,s32-swt";  /* in zephyr/dts/arm/nxp/nxp_s32k344_m7.dtsi:897 */
			reg = < 0x40270000 0x4000 >; /* in zephyr/dts/arm/nxp/nxp_s32k344_m7.dtsi:898 */
			interrupts = < 0x2a 0x0 >;   /* in zephyr/dts/arm/nxp/nxp_s32k344_m7.dtsi:899 */
			clocks = < &clock 0x3 >;     /* in zephyr/dts/arm/nxp/nxp_s32k344_m7.dtsi:900 */
			service-mode = "fixed";      /* in zephyr/dts/arm/nxp/nxp_s32k344_m7.dtsi:901 */
			status = "okay";             /* in zephyr/dts/arm/nxp/nxp_s32k344_m7.dtsi:902 */
		};

		/* node '/soc/stm@40274000' defined in zephyr/dts/arm/nxp/nxp_s32k344_m7.dtsi:905 */
		stm0: stm@40274000 {
			compatible = "nxp,s32-sys-timer"; /* in zephyr/dts/arm/nxp/nxp_s32k344_m7.dtsi:906 */
			reg = < 0x40274000 0x10000 >;     /* in zephyr/dts/arm/nxp/nxp_s32k344_m7.dtsi:907 */
			interrupts = < 0x27 0x0 >;        /* in zephyr/dts/arm/nxp/nxp_s32k344_m7.dtsi:908 */
			clocks = < &clock 0x85 >;         /* in zephyr/dts/arm/nxp/nxp_s32k344_m7.dtsi:909 */
			status = "disabled";              /* in zephyr/dts/arm/nxp/nxp_s32k344_m7.dtsi:910 */
		};

		/* node '/soc/stm@40474000' defined in zephyr/dts/arm/nxp/nxp_s32k344_m7.dtsi:913 */
		stm1: stm@40474000 {
			compatible = "nxp,s32-sys-timer"; /* in zephyr/dts/arm/nxp/nxp_s32k344_m7.dtsi:914 */
			reg = < 0x40474000 0x10000 >;     /* in zephyr/dts/arm/nxp/nxp_s32k344_m7.dtsi:915 */
			interrupts = < 0x28 0x0 >;        /* in zephyr/dts/arm/nxp/nxp_s32k344_m7.dtsi:916 */
			clocks = < &clock 0x87 >;         /* in zephyr/dts/arm/nxp/nxp_s32k344_m7.dtsi:917 */
			status = "disabled";              /* in zephyr/dts/arm/nxp/nxp_s32k344_m7.dtsi:918 */
		};
	};

	/* node '/cpus' defined in zephyr/dts/arm/nxp/nxp_s32k344_m7.dtsi:15 */
	cpus {
		#address-cells = < 0x1 >; /* in zephyr/dts/arm/nxp/nxp_s32k344_m7.dtsi:16 */
		#size-cells = < 0x0 >;    /* in zephyr/dts/arm/nxp/nxp_s32k344_m7.dtsi:17 */

		/* node '/cpus/cpu@0' defined in zephyr/dts/arm/nxp/nxp_s32k344_m7.dtsi:19 */
		cpu@0 {
			device_type = "cpu";          /* in zephyr/dts/arm/nxp/nxp_s32k344_m7.dtsi:20 */
			compatible = "arm,cortex-m7"; /* in zephyr/dts/arm/nxp/nxp_s32k344_m7.dtsi:21 */
			reg = < 0x0 >;                /* in zephyr/dts/arm/nxp/nxp_s32k344_m7.dtsi:22 */
		};

		/* node '/cpus/cpu@1' defined in zephyr/dts/arm/nxp/nxp_s32k344_m7.dtsi:25 */
		cpu@1 {
			device_type = "cpu";          /* in zephyr/dts/arm/nxp/nxp_s32k344_m7.dtsi:26 */
			compatible = "arm,cortex-m7"; /* in zephyr/dts/arm/nxp/nxp_s32k344_m7.dtsi:27 */
			reg = < 0x1 >;                /* in zephyr/dts/arm/nxp/nxp_s32k344_m7.dtsi:28 */
		};

		/* node '/cpus/mpu@e000ed90' defined in zephyr/dts/arm/nxp/nxp_s32k344_m7.dtsi:31 */
		mpu: mpu@e000ed90 {
			compatible = "arm,armv7m-mpu"; /* in zephyr/dts/arm/nxp/nxp_s32k344_m7.dtsi:32 */
			reg = < 0xe000ed90 0x40 >;     /* in zephyr/dts/arm/nxp/nxp_s32k344_m7.dtsi:33 */
		};
	};

	/* node '/pinctrl' defined in zephyr/dts/arm/nxp/nxp_s32k344_m7.dtsi:38 */
	pinctrl: pinctrl {
		compatible = "nxp,s32k3-siul2-pinctrl"; /* in zephyr/dts/arm/nxp/nxp_s32k344_m7.dtsi:39 */
		status = "okay";                        /* in zephyr/dts/arm/nxp/nxp_s32k344_m7.dtsi:40 */

		/* node '/pinctrl/eirq0_default' defined in zephyr/boards/nxp/mr_canhubk3/mr_canhubk3-pinctrl.dtsi:10 */
		eirq0_default: eirq0_default {
			phandle = < 0x2 >; /* in zephyr/boards/nxp/mr_canhubk3/mr_canhubk3.dts:271 */

			/* node '/pinctrl/eirq0_default/group1' defined in zephyr/boards/nxp/mr_canhubk3/mr_canhubk3-pinctrl.dtsi:11 */
			group1 {
				pinmux = < 0x6f1790 >,
				         < 0x120810 >,
				         < 0x170a90 >,
				         < 0x650e98 >; /* in zephyr/boards/nxp/mr_canhubk3/mr_canhubk3-pinctrl.dtsi:12 */
				input-enable;          /* in zephyr/boards/nxp/mr_canhubk3/mr_canhubk3-pinctrl.dtsi:13 */
			};
		};

		/* node '/pinctrl/lpuart0_default' defined in zephyr/boards/nxp/mr_canhubk3/mr_canhubk3-pinctrl.dtsi:17 */
		lpuart0_default: lpuart0_default {
			phandle = < 0x6 >; /* in zephyr/boards/nxp/mr_canhubk3/mr_canhubk3.dts:277 */

			/* node '/pinctrl/lpuart0_default/group1' defined in zephyr/boards/nxp/mr_canhubk3/mr_canhubk3-pinctrl.dtsi:18 */
			group1 {
				pinmux = < 0x30006 >,
				         < 0x10003 >; /* in zephyr/boards/nxp/mr_canhubk3/mr_canhubk3-pinctrl.dtsi:19 */
				output-enable;        /* in zephyr/boards/nxp/mr_canhubk3/mr_canhubk3-pinctrl.dtsi:20 */
			};

			/* node '/pinctrl/lpuart0_default/group2' defined in zephyr/boards/nxp/mr_canhubk3/mr_canhubk3-pinctrl.dtsi:23 */
			group2 {
				pinmux = < 0x25d88 >,
				         < 0xb408 >;  /* in zephyr/boards/nxp/mr_canhubk3/mr_canhubk3-pinctrl.dtsi:24 */
				input-enable;         /* in zephyr/boards/nxp/mr_canhubk3/mr_canhubk3-pinctrl.dtsi:25 */
			};
		};

		/* node '/pinctrl/lpuart1_default' defined in zephyr/boards/nxp/mr_canhubk3/mr_canhubk3-pinctrl.dtsi:29 */
		lpuart1_default: lpuart1_default {
			phandle = < 0x8 >; /* in zephyr/boards/nxp/mr_canhubk3/mr_canhubk3.dts:284 */

			/* node '/pinctrl/lpuart1_default/group1' defined in zephyr/boards/nxp/mr_canhubk3/mr_canhubk3-pinctrl.dtsi:30 */
			group1 {
				pinmux = < 0x470002 >,
				         < 0x860003 >; /* in zephyr/boards/nxp/mr_canhubk3/mr_canhubk3-pinctrl.dtsi:31 */
				output-enable;         /* in zephyr/boards/nxp/mr_canhubk3/mr_canhubk3-pinctrl.dtsi:32 */
			};

			/* node '/pinctrl/lpuart1_default/group2' defined in zephyr/boards/nxp/mr_canhubk3/mr_canhubk3-pinctrl.dtsi:35 */
			group2 {
				pinmux = < 0x465e08 >,
				         < 0x82b488 >; /* in zephyr/boards/nxp/mr_canhubk3/mr_canhubk3-pinctrl.dtsi:36 */
				input-enable;          /* in zephyr/boards/nxp/mr_canhubk3/mr_canhubk3-pinctrl.dtsi:37 */
			};
		};

		/* node '/pinctrl/lpuart2_default' defined in zephyr/boards/nxp/mr_canhubk3/mr_canhubk3-pinctrl.dtsi:41 */
		lpuart2_default: lpuart2_default {
			phandle = < 0x9 >; /* in zephyr/boards/nxp/mr_canhubk3/mr_canhubk3.dts:291 */

			/* node '/pinctrl/lpuart2_default/group1' defined in zephyr/boards/nxp/mr_canhubk3/mr_canhubk3-pinctrl.dtsi:42 */
			group1 {
				pinmux = < 0x90002 >; /* in zephyr/boards/nxp/mr_canhubk3/mr_canhubk3-pinctrl.dtsi:43 */
				output-enable;        /* in zephyr/boards/nxp/mr_canhubk3/mr_canhubk3-pinctrl.dtsi:44 */
			};

			/* node '/pinctrl/lpuart2_default/group2' defined in zephyr/boards/nxp/mr_canhubk3/mr_canhubk3-pinctrl.dtsi:47 */
			group2 {
				pinmux = < 0x85e98 >; /* in zephyr/boards/nxp/mr_canhubk3/mr_canhubk3-pinctrl.dtsi:48 */
				input-enable;         /* in zephyr/boards/nxp/mr_canhubk3/mr_canhubk3-pinctrl.dtsi:49 */
			};
		};

		/* node '/pinctrl/lpuart9_default' defined in zephyr/boards/nxp/mr_canhubk3/mr_canhubk3-pinctrl.dtsi:53 */
		lpuart9_default: lpuart9_default {
			phandle = < 0xa >; /* in zephyr/boards/nxp/mr_canhubk3/mr_canhubk3.dts:300 */

			/* node '/pinctrl/lpuart9_default/group1' defined in zephyr/boards/nxp/mr_canhubk3/mr_canhubk3-pinctrl.dtsi:54 */
			group1 {
				pinmux = < 0x230001 >; /* in zephyr/boards/nxp/mr_canhubk3/mr_canhubk3-pinctrl.dtsi:55 */
				output-enable;         /* in zephyr/boards/nxp/mr_canhubk3/mr_canhubk3-pinctrl.dtsi:56 */
			};

			/* node '/pinctrl/lpuart9_default/group2' defined in zephyr/boards/nxp/mr_canhubk3/mr_canhubk3-pinctrl.dtsi:59 */
			group2 {
				pinmux = < 0x226210 >; /* in zephyr/boards/nxp/mr_canhubk3/mr_canhubk3-pinctrl.dtsi:60 */
				input-enable;          /* in zephyr/boards/nxp/mr_canhubk3/mr_canhubk3-pinctrl.dtsi:61 */
			};
		};

		/* node '/pinctrl/lpuart10_default' defined in zephyr/boards/nxp/mr_canhubk3/mr_canhubk3-pinctrl.dtsi:65 */
		lpuart10_default: lpuart10_default {
			phandle = < 0xb >; /* in zephyr/boards/nxp/mr_canhubk3/mr_canhubk3.dts:312 */

			/* node '/pinctrl/lpuart10_default/group1' defined in zephyr/boards/nxp/mr_canhubk3/mr_canhubk3-pinctrl.dtsi:66 */
			group1 {
				pinmux = < 0x4d0001 >; /* in zephyr/boards/nxp/mr_canhubk3/mr_canhubk3-pinctrl.dtsi:67 */
				output-enable;         /* in zephyr/boards/nxp/mr_canhubk3/mr_canhubk3-pinctrl.dtsi:68 */
			};

			/* node '/pinctrl/lpuart10_default/group2' defined in zephyr/boards/nxp/mr_canhubk3/mr_canhubk3-pinctrl.dtsi:71 */
			group2 {
				pinmux = < 0x4c6290 >; /* in zephyr/boards/nxp/mr_canhubk3/mr_canhubk3-pinctrl.dtsi:72 */
				input-enable;          /* in zephyr/boards/nxp/mr_canhubk3/mr_canhubk3-pinctrl.dtsi:73 */
			};
		};

		/* node '/pinctrl/lpuart13_default' defined in zephyr/boards/nxp/mr_canhubk3/mr_canhubk3-pinctrl.dtsi:77 */
		lpuart13_default: lpuart13_default {
			phandle = < 0xc >; /* in zephyr/boards/nxp/mr_canhubk3/mr_canhubk3.dts:324 */

			/* node '/pinctrl/lpuart13_default/group1' defined in zephyr/boards/nxp/mr_canhubk3/mr_canhubk3-pinctrl.dtsi:78 */
			group1 {
				pinmux = < 0x320001 >; /* in zephyr/boards/nxp/mr_canhubk3/mr_canhubk3-pinctrl.dtsi:79 */
				output-enable;         /* in zephyr/boards/nxp/mr_canhubk3/mr_canhubk3-pinctrl.dtsi:80 */
			};

			/* node '/pinctrl/lpuart13_default/group2' defined in zephyr/boards/nxp/mr_canhubk3/mr_canhubk3-pinctrl.dtsi:83 */
			group2 {
				pinmux = < 0x336408 >; /* in zephyr/boards/nxp/mr_canhubk3/mr_canhubk3-pinctrl.dtsi:84 */
				input-enable;          /* in zephyr/boards/nxp/mr_canhubk3/mr_canhubk3-pinctrl.dtsi:85 */
			};
		};

		/* node '/pinctrl/lpuart14_default' defined in zephyr/boards/nxp/mr_canhubk3/mr_canhubk3-pinctrl.dtsi:89 */
		lpuart14_default: lpuart14_default {
			phandle = < 0xd >; /* in zephyr/boards/nxp/mr_canhubk3/mr_canhubk3.dts:331 */

			/* node '/pinctrl/lpuart14_default/group1' defined in zephyr/boards/nxp/mr_canhubk3/mr_canhubk3-pinctrl.dtsi:90 */
			group1 {
				pinmux = < 0x340001 >; /* in zephyr/boards/nxp/mr_canhubk3/mr_canhubk3-pinctrl.dtsi:91 */
				output-enable;         /* in zephyr/boards/nxp/mr_canhubk3/mr_canhubk3-pinctrl.dtsi:92 */
			};

			/* node '/pinctrl/lpuart14_default/group2' defined in zephyr/boards/nxp/mr_canhubk3/mr_canhubk3-pinctrl.dtsi:95 */
			group2 {
				pinmux = < 0x356488 >; /* in zephyr/boards/nxp/mr_canhubk3/mr_canhubk3-pinctrl.dtsi:96 */
				input-enable;          /* in zephyr/boards/nxp/mr_canhubk3/mr_canhubk3-pinctrl.dtsi:97 */
			};
		};

		/* node '/pinctrl/qspi0_default' defined in zephyr/boards/nxp/mr_canhubk3/mr_canhubk3-pinctrl.dtsi:101 */
		qspi0_default: qspi0_default {
			phandle = < 0xe >; /* in zephyr/boards/nxp/mr_canhubk3/mr_canhubk3.dts:338 */

			/* node '/pinctrl/qspi0_default/group1' defined in zephyr/boards/nxp/mr_canhubk3/mr_canhubk3-pinctrl.dtsi:102 */
			group1 {
				pinmux = < 0x6b988f >,
				         < 0x67990f >,
				         < 0x6c998f >,
				         < 0x429a0f >; /* in zephyr/boards/nxp/mr_canhubk3/mr_canhubk3-pinctrl.dtsi:103 */
				output-enable;         /* in zephyr/boards/nxp/mr_canhubk3/mr_canhubk3-pinctrl.dtsi:107 */
				input-enable;          /* in zephyr/boards/nxp/mr_canhubk3/mr_canhubk3-pinctrl.dtsi:108 */
			};

			/* node '/pinctrl/qspi0_default/group2' defined in zephyr/boards/nxp/mr_canhubk3/mr_canhubk3-pinctrl.dtsi:111 */
			group2 {
				pinmux = < 0x6a0007 >; /* in zephyr/boards/nxp/mr_canhubk3/mr_canhubk3-pinctrl.dtsi:112 */
				output-enable;         /* in zephyr/boards/nxp/mr_canhubk3/mr_canhubk3-pinctrl.dtsi:113 */
			};

			/* node '/pinctrl/qspi0_default/group3' defined in zephyr/boards/nxp/mr_canhubk3/mr_canhubk3-pinctrl.dtsi:116 */
			group3 {
				pinmux = < 0x430006 >; /* in zephyr/boards/nxp/mr_canhubk3/mr_canhubk3-pinctrl.dtsi:117 */
				output-enable;         /* in zephyr/boards/nxp/mr_canhubk3/mr_canhubk3-pinctrl.dtsi:118 */
				bias-pull-up;          /* in zephyr/boards/nxp/mr_canhubk3/mr_canhubk3-pinctrl.dtsi:119 */
			};
		};

		/* node '/pinctrl/flexcan0_default' defined in zephyr/boards/nxp/mr_canhubk3/mr_canhubk3-pinctrl.dtsi:123 */
		flexcan0_default: flexcan0_default {
			phandle = < 0xf >; /* in zephyr/boards/nxp/mr_canhubk3/mr_canhubk3.dts:375 */

			/* node '/pinctrl/flexcan0_default/group1' defined in zephyr/boards/nxp/mr_canhubk3/mr_canhubk3-pinctrl.dtsi:124 */
			group1 {
				pinmux = < 0x60010 >; /* in zephyr/boards/nxp/mr_canhubk3/mr_canhubk3-pinctrl.dtsi:125 */
				input-enable;         /* in zephyr/boards/nxp/mr_canhubk3/mr_canhubk3-pinctrl.dtsi:126 */
			};

			/* node '/pinctrl/flexcan0_default/group2' defined in zephyr/boards/nxp/mr_canhubk3/mr_canhubk3-pinctrl.dtsi:129 */
			group2 {
				pinmux = < 0x70004 >; /* in zephyr/boards/nxp/mr_canhubk3/mr_canhubk3-pinctrl.dtsi:130 */
				output-enable;        /* in zephyr/boards/nxp/mr_canhubk3/mr_canhubk3-pinctrl.dtsi:131 */
			};
		};

		/* node '/pinctrl/flexcan1_default' defined in zephyr/boards/nxp/mr_canhubk3/mr_canhubk3-pinctrl.dtsi:135 */
		flexcan1_default: flexcan1_default {
			phandle = < 0x11 >; /* in zephyr/boards/nxp/mr_canhubk3/mr_canhubk3.dts:382 */

			/* node '/pinctrl/flexcan1_default/group1' defined in zephyr/boards/nxp/mr_canhubk3/mr_canhubk3-pinctrl.dtsi:136 */
			group1 {
				pinmux = < 0x490088 >; /* in zephyr/boards/nxp/mr_canhubk3/mr_canhubk3-pinctrl.dtsi:137 */
				input-enable;          /* in zephyr/boards/nxp/mr_canhubk3/mr_canhubk3-pinctrl.dtsi:138 */
			};

			/* node '/pinctrl/flexcan1_default/group2' defined in zephyr/boards/nxp/mr_canhubk3/mr_canhubk3-pinctrl.dtsi:141 */
			group2 {
				pinmux = < 0x480003 >; /* in zephyr/boards/nxp/mr_canhubk3/mr_canhubk3-pinctrl.dtsi:142 */
				output-enable;         /* in zephyr/boards/nxp/mr_canhubk3/mr_canhubk3-pinctrl.dtsi:143 */
			};
		};

		/* node '/pinctrl/flexcan2_default' defined in zephyr/boards/nxp/mr_canhubk3/mr_canhubk3-pinctrl.dtsi:147 */
		flexcan2_default: flexcan2_default {
			phandle = < 0x13 >; /* in zephyr/boards/nxp/mr_canhubk3/mr_canhubk3.dts:388 */

			/* node '/pinctrl/flexcan2_default/group1' defined in zephyr/boards/nxp/mr_canhubk3/mr_canhubk3-pinctrl.dtsi:148 */
			group1 {
				pinmux = < 0x990118 >; /* in zephyr/boards/nxp/mr_canhubk3/mr_canhubk3-pinctrl.dtsi:149 */
				input-enable;          /* in zephyr/boards/nxp/mr_canhubk3/mr_canhubk3-pinctrl.dtsi:150 */
			};

			/* node '/pinctrl/flexcan2_default/group2' defined in zephyr/boards/nxp/mr_canhubk3/mr_canhubk3-pinctrl.dtsi:153 */
			group2 {
				pinmux = < 0x980003 >; /* in zephyr/boards/nxp/mr_canhubk3/mr_canhubk3-pinctrl.dtsi:154 */
				output-enable;         /* in zephyr/boards/nxp/mr_canhubk3/mr_canhubk3-pinctrl.dtsi:155 */
			};
		};

		/* node '/pinctrl/flexcan3_default' defined in zephyr/boards/nxp/mr_canhubk3/mr_canhubk3-pinctrl.dtsi:159 */
		flexcan3_default: flexcan3_default {
			phandle = < 0x15 >; /* in zephyr/boards/nxp/mr_canhubk3/mr_canhubk3.dts:394 */

			/* node '/pinctrl/flexcan3_default/group1' defined in zephyr/boards/nxp/mr_canhubk3/mr_canhubk3-pinctrl.dtsi:160 */
			group1 {
				pinmux = < 0x5d0198 >; /* in zephyr/boards/nxp/mr_canhubk3/mr_canhubk3-pinctrl.dtsi:161 */
				input-enable;          /* in zephyr/boards/nxp/mr_canhubk3/mr_canhubk3-pinctrl.dtsi:162 */
			};

			/* node '/pinctrl/flexcan3_default/group2' defined in zephyr/boards/nxp/mr_canhubk3/mr_canhubk3-pinctrl.dtsi:165 */
			group2 {
				pinmux = < 0x5c0001 >; /* in zephyr/boards/nxp/mr_canhubk3/mr_canhubk3-pinctrl.dtsi:166 */
				output-enable;         /* in zephyr/boards/nxp/mr_canhubk3/mr_canhubk3-pinctrl.dtsi:167 */
			};
		};

		/* node '/pinctrl/flexcan4_default' defined in zephyr/boards/nxp/mr_canhubk3/mr_canhubk3-pinctrl.dtsi:171 */
		flexcan4_default: flexcan4_default {
			phandle = < 0x17 >; /* in zephyr/boards/nxp/mr_canhubk3/mr_canhubk3.dts:400 */

			/* node '/pinctrl/flexcan4_default/group1' defined in zephyr/boards/nxp/mr_canhubk3/mr_canhubk3-pinctrl.dtsi:172 */
			group1 {
				pinmux = < 0x5f0218 >; /* in zephyr/boards/nxp/mr_canhubk3/mr_canhubk3-pinctrl.dtsi:173 */
				input-enable;          /* in zephyr/boards/nxp/mr_canhubk3/mr_canhubk3-pinctrl.dtsi:174 */
			};

			/* node '/pinctrl/flexcan4_default/group2' defined in zephyr/boards/nxp/mr_canhubk3/mr_canhubk3-pinctrl.dtsi:177 */
			group2 {
				pinmux = < 0x5e0001 >; /* in zephyr/boards/nxp/mr_canhubk3/mr_canhubk3-pinctrl.dtsi:178 */
				output-enable;         /* in zephyr/boards/nxp/mr_canhubk3/mr_canhubk3-pinctrl.dtsi:179 */
			};
		};

		/* node '/pinctrl/flexcan5_default' defined in zephyr/boards/nxp/mr_canhubk3/mr_canhubk3-pinctrl.dtsi:183 */
		flexcan5_default: flexcan5_default {
			phandle = < 0x19 >; /* in zephyr/boards/nxp/mr_canhubk3/mr_canhubk3.dts:406 */

			/* node '/pinctrl/flexcan5_default/group1' defined in zephyr/boards/nxp/mr_canhubk3/mr_canhubk3-pinctrl.dtsi:184 */
			group1 {
				pinmux = < 0x4b0290 >; /* in zephyr/boards/nxp/mr_canhubk3/mr_canhubk3-pinctrl.dtsi:185 */
				input-enable;          /* in zephyr/boards/nxp/mr_canhubk3/mr_canhubk3-pinctrl.dtsi:186 */
			};

			/* node '/pinctrl/flexcan5_default/group2' defined in zephyr/boards/nxp/mr_canhubk3/mr_canhubk3-pinctrl.dtsi:189 */
			group2 {
				pinmux = < 0x4a0003 >; /* in zephyr/boards/nxp/mr_canhubk3/mr_canhubk3-pinctrl.dtsi:190 */
				output-enable;         /* in zephyr/boards/nxp/mr_canhubk3/mr_canhubk3-pinctrl.dtsi:191 */
			};
		};

		/* node '/pinctrl/lpi2c0_default' defined in zephyr/boards/nxp/mr_canhubk3/mr_canhubk3-pinctrl.dtsi:195 */
		lpi2c0_default: lpi2c0_default {
			phandle = < 0x1b >; /* in zephyr/boards/nxp/mr_canhubk3/mr_canhubk3.dts:412 */

			/* node '/pinctrl/lpi2c0_default/group1' defined in zephyr/boards/nxp/mr_canhubk3/mr_canhubk3-pinctrl.dtsi:196 */
			group1 {
				pinmux = < 0x6d6b14 >,
				         < 0x6e6a14 >; /* in zephyr/boards/nxp/mr_canhubk3/mr_canhubk3-pinctrl.dtsi:197 */
				input-enable;          /* in zephyr/boards/nxp/mr_canhubk3/mr_canhubk3-pinctrl.dtsi:199 */
				output-enable;         /* in zephyr/boards/nxp/mr_canhubk3/mr_canhubk3-pinctrl.dtsi:200 */
			};
		};

		/* node '/pinctrl/lpi2c1_default' defined in zephyr/boards/nxp/mr_canhubk3/mr_canhubk3-pinctrl.dtsi:204 */
		lpi2c1_default: lpi2c1_default {
			phandle = < 0x1c >; /* in zephyr/boards/nxp/mr_canhubk3/mr_canhubk3.dts:434 */

			/* node '/pinctrl/lpi2c1_default/group1' defined in zephyr/boards/nxp/mr_canhubk3/mr_canhubk3-pinctrl.dtsi:205 */
			group1 {
				pinmux = < 0x686d8a >,
				         < 0x696c92 >; /* in zephyr/boards/nxp/mr_canhubk3/mr_canhubk3-pinctrl.dtsi:206 */
				input-enable;          /* in zephyr/boards/nxp/mr_canhubk3/mr_canhubk3-pinctrl.dtsi:208 */
				output-enable;         /* in zephyr/boards/nxp/mr_canhubk3/mr_canhubk3-pinctrl.dtsi:209 */
			};
		};

		/* node '/pinctrl/lpspi1_default' defined in zephyr/boards/nxp/mr_canhubk3/mr_canhubk3-pinctrl.dtsi:213 */
		lpspi1_default: lpspi1_default {
			phandle = < 0x1d >; /* in zephyr/boards/nxp/mr_canhubk3/mr_canhubk3.dts:440 */

			/* node '/pinctrl/lpspi1_default/group1' defined in zephyr/boards/nxp/mr_canhubk3/mr_canhubk3-pinctrl.dtsi:214 */
			group1 {
				pinmux = < 0x1c0003 >,
				         < 0x1d0005 >,
				         < 0x150004 >,
				         < 0x840002 >; /* in zephyr/boards/nxp/mr_canhubk3/mr_canhubk3-pinctrl.dtsi:215 */
				output-enable;         /* in zephyr/boards/nxp/mr_canhubk3/mr_canhubk3-pinctrl.dtsi:217 */
			};

			/* node '/pinctrl/lpspi1_default/group2' defined in zephyr/boards/nxp/mr_canhubk3/mr_canhubk3-pinctrl.dtsi:220 */
			group2 {
				pinmux = < 0x1e7828 >; /* in zephyr/boards/nxp/mr_canhubk3/mr_canhubk3-pinctrl.dtsi:221 */
				input-enable;          /* in zephyr/boards/nxp/mr_canhubk3/mr_canhubk3-pinctrl.dtsi:222 */
			};
		};

		/* node '/pinctrl/lpspi2_default' defined in zephyr/boards/nxp/mr_canhubk3/mr_canhubk3-pinctrl.dtsi:226 */
		lpspi2_default: lpspi2_default {
			phandle = < 0x1e >; /* in zephyr/boards/nxp/mr_canhubk3/mr_canhubk3.dts:446 */

			/* node '/pinctrl/lpspi2_default/group1' defined in zephyr/boards/nxp/mr_canhubk3/mr_canhubk3-pinctrl.dtsi:227 */
			group1 {
				pinmux = < 0x3d0005 >,
				         < 0x3c0005 >,
				         < 0x390005 >,
				         < 0x530005 >; /* in zephyr/boards/nxp/mr_canhubk3/mr_canhubk3-pinctrl.dtsi:228 */
				output-enable;         /* in zephyr/boards/nxp/mr_canhubk3/mr_canhubk3-pinctrl.dtsi:230 */
			};

			/* node '/pinctrl/lpspi2_default/group2' defined in zephyr/boards/nxp/mr_canhubk3/mr_canhubk3-pinctrl.dtsi:233 */
			group2 {
				pinmux = < 0x3b7b98 >; /* in zephyr/boards/nxp/mr_canhubk3/mr_canhubk3-pinctrl.dtsi:234 */
				input-enable;          /* in zephyr/boards/nxp/mr_canhubk3/mr_canhubk3-pinctrl.dtsi:235 */
			};
		};

		/* node '/pinctrl/lpspi3_default' defined in zephyr/boards/nxp/mr_canhubk3/mr_canhubk3-pinctrl.dtsi:239 */
		lpspi3_default: lpspi3_default {
			phandle = < 0x1f >; /* in zephyr/boards/nxp/mr_canhubk3/mr_canhubk3.dts:452 */

			/* node '/pinctrl/lpspi3_default/group1' defined in zephyr/boards/nxp/mr_canhubk3/mr_canhubk3-pinctrl.dtsi:240 */
			group1 {
				pinmux = < 0x610003 >,
				         < 0x8a0002 >,
				         < 0x710005 >; /* in zephyr/boards/nxp/mr_canhubk3/mr_canhubk3-pinctrl.dtsi:241 */
				output-enable;         /* in zephyr/boards/nxp/mr_canhubk3/mr_canhubk3-pinctrl.dtsi:243 */
			};

			/* node '/pinctrl/lpspi3_default/group2' defined in zephyr/boards/nxp/mr_canhubk3/mr_canhubk3-pinctrl.dtsi:246 */
			group2 {
				pinmux = < 0x607f08 >; /* in zephyr/boards/nxp/mr_canhubk3/mr_canhubk3-pinctrl.dtsi:247 */
				input-enable;          /* in zephyr/boards/nxp/mr_canhubk3/mr_canhubk3-pinctrl.dtsi:248 */
			};
		};

		/* node '/pinctrl/lpspi4_default' defined in zephyr/boards/nxp/mr_canhubk3/mr_canhubk3-pinctrl.dtsi:252 */
		lpspi4_default: lpspi4_default {
			phandle = < 0x21 >; /* in zephyr/boards/nxp/mr_canhubk3/mr_canhubk3.dts:468 */

			/* node '/pinctrl/lpspi4_default/group1' defined in zephyr/boards/nxp/mr_canhubk3/mr_canhubk3-pinctrl.dtsi:253 */
			group1 {
				pinmux = < 0x2a0001 >,
				         < 0x2b0001 >,
				         < 0x280001 >; /* in zephyr/boards/nxp/mr_canhubk3/mr_canhubk3-pinctrl.dtsi:254 */
				output-enable;         /* in zephyr/boards/nxp/mr_canhubk3/mr_canhubk3-pinctrl.dtsi:256 */
			};

			/* node '/pinctrl/lpspi4_default/group2' defined in zephyr/boards/nxp/mr_canhubk3/mr_canhubk3-pinctrl.dtsi:259 */
			group2 {
				pinmux = < 0x298290 >; /* in zephyr/boards/nxp/mr_canhubk3/mr_canhubk3-pinctrl.dtsi:260 */
				input-enable;          /* in zephyr/boards/nxp/mr_canhubk3/mr_canhubk3-pinctrl.dtsi:261 */
			};
		};

		/* node '/pinctrl/lpspi5_default' defined in zephyr/boards/nxp/mr_canhubk3/mr_canhubk3-pinctrl.dtsi:265 */
		lpspi5_default: lpspi5_default {
			phandle = < 0x22 >; /* in zephyr/boards/nxp/mr_canhubk3/mr_canhubk3.dts:474 */

			/* node '/pinctrl/lpspi5_default/group1' defined in zephyr/boards/nxp/mr_canhubk3/mr_canhubk3-pinctrl.dtsi:266 */
			group1 {
				pinmux = < 0x7a0006 >,
				         < 0x7c0006 >; /* in zephyr/boards/nxp/mr_canhubk3/mr_canhubk3-pinctrl.dtsi:267 */
				output-enable;         /* in zephyr/boards/nxp/mr_canhubk3/mr_canhubk3-pinctrl.dtsi:268 */
			};

			/* node '/pinctrl/lpspi5_default/group2' defined in zephyr/boards/nxp/mr_canhubk3/mr_canhubk3-pinctrl.dtsi:271 */
			group2 {
				pinmux = < 0x7b8618 >; /* in zephyr/boards/nxp/mr_canhubk3/mr_canhubk3-pinctrl.dtsi:272 */
				input-enable;          /* in zephyr/boards/nxp/mr_canhubk3/mr_canhubk3-pinctrl.dtsi:273 */
			};
		};

		/* node '/pinctrl/emac0_default' defined in zephyr/boards/nxp/mr_canhubk3/mr_canhubk3-pinctrl.dtsi:277 */
		emac0_default: emac0_default {
			phandle = < 0x23 >; /* in zephyr/boards/nxp/mr_canhubk3/mr_canhubk3.dts:480 */

			/* node '/pinctrl/emac0_default/group1' defined in zephyr/boards/nxp/mr_canhubk3/mr_canhubk3-pinctrl.dtsi:278 */
			group1 {
				pinmux = < 0x409310 >,
				         < 0x419390 >,
				         < 0x4e9290 >,
				         < 0x4f9210 >,
				         < 0x669410 >; /* in zephyr/boards/nxp/mr_canhubk3/mr_canhubk3-pinctrl.dtsi:279 */
				input-enable;          /* in zephyr/boards/nxp/mr_canhubk3/mr_canhubk3-pinctrl.dtsi:284 */
			};

			/* node '/pinctrl/emac0_default/group2' defined in zephyr/boards/nxp/mr_canhubk3/mr_canhubk3-pinctrl.dtsi:287 */
			group2 {
				pinmux = < 0x250001 >,
				         < 0x240001 >,
				         < 0x890006 >; /* in zephyr/boards/nxp/mr_canhubk3/mr_canhubk3-pinctrl.dtsi:288 */
			};
		};

		/* node '/pinctrl/mdio0_default' defined in zephyr/boards/nxp/mr_canhubk3/mr_canhubk3-pinctrl.dtsi:294 */
		mdio0_default: mdio0_default {
			phandle = < 0x25 >; /* in zephyr/boards/nxp/mr_canhubk3/mr_canhubk3.dts:489 */

			/* node '/pinctrl/mdio0_default/group1' defined in zephyr/boards/nxp/mr_canhubk3/mr_canhubk3-pinctrl.dtsi:295 */
			group1 {
				pinmux = < 0x709193 >; /* in zephyr/boards/nxp/mr_canhubk3/mr_canhubk3-pinctrl.dtsi:296 */
				input-enable;          /* in zephyr/boards/nxp/mr_canhubk3/mr_canhubk3-pinctrl.dtsi:297 */
				output-enable;         /* in zephyr/boards/nxp/mr_canhubk3/mr_canhubk3-pinctrl.dtsi:298 */
			};

			/* node '/pinctrl/mdio0_default/group2' defined in zephyr/boards/nxp/mr_canhubk3/mr_canhubk3-pinctrl.dtsi:301 */
			group2 {
				pinmux = < 0x880005 >; /* in zephyr/boards/nxp/mr_canhubk3/mr_canhubk3-pinctrl.dtsi:302 */
				output-enable;         /* in zephyr/boards/nxp/mr_canhubk3/mr_canhubk3-pinctrl.dtsi:303 */
			};
		};

		/* node '/pinctrl/emios0_default' defined in zephyr/boards/nxp/mr_canhubk3/mr_canhubk3-pinctrl.dtsi:307 */
		emios0_default: emios0_default {
			phandle = < 0x27 >; /* in zephyr/boards/nxp/mr_canhubk3/mr_canhubk3.dts:519 */

			/* node '/pinctrl/emios0_default/group1' defined in zephyr/boards/nxp/mr_canhubk3/mr_canhubk3-pinctrl.dtsi:308 */
			group1 {
				pinmux = < 0x2c0002 >,
				         < 0x2d0002 >,
				         < 0x2e0002 >,
				         < 0x2f0002 >,
				         < 0x300002 >,
				         < 0x310002 >,
				         < 0x8e0001 >; /* in zephyr/boards/nxp/mr_canhubk3/mr_canhubk3-pinctrl.dtsi:309 */
				output-enable;         /* in zephyr/boards/nxp/mr_canhubk3/mr_canhubk3-pinctrl.dtsi:313 */
			};
		};

		/* node '/pinctrl/emios1_default' defined in zephyr/boards/nxp/mr_canhubk3/mr_canhubk3-pinctrl.dtsi:317 */
		emios1_default: emios1_default {
			phandle = < 0x29 >; /* in zephyr/boards/nxp/mr_canhubk3/mr_canhubk3.dts:591 */

			/* node '/pinctrl/emios1_default/group1' defined in zephyr/boards/nxp/mr_canhubk3/mr_canhubk3-pinctrl.dtsi:318 */
			group1 {
				pinmux = < 0x1b0002 >,
				         < 0x8c0004 >; /* in zephyr/boards/nxp/mr_canhubk3/mr_canhubk3-pinctrl.dtsi:319 */
				output-enable;         /* in zephyr/boards/nxp/mr_canhubk3/mr_canhubk3-pinctrl.dtsi:321 */
			};
		};

		/* node '/pinctrl/flexio0_pwm_default' defined in zephyr/boards/nxp/mr_canhubk3/mr_canhubk3-pinctrl.dtsi:325 */
		flexio0_pwm_default: flexio0_pwm_default {
			phandle = < 0x2c >; /* in zephyr/boards/nxp/mr_canhubk3/mr_canhubk3.dts:613 */

			/* node '/pinctrl/flexio0_pwm_default/group1' defined in zephyr/boards/nxp/mr_canhubk3/mr_canhubk3-pinctrl.dtsi:326 */
			group1 {
				pinmux = < 0x110007 >,
				         < 0x870007 >; /* in zephyr/boards/nxp/mr_canhubk3/mr_canhubk3-pinctrl.dtsi:327 */
				output-enable;         /* in zephyr/boards/nxp/mr_canhubk3/mr_canhubk3-pinctrl.dtsi:328 */
			};
		};

		/* node '/pinctrl/qdec_s32' defined in zephyr/boards/nxp/mr_canhubk3/mr_canhubk3-pinctrl.dtsi:332 */
		qdec_s32: qdec_s32 {
			phandle = < 0x33 >; /* in zephyr/boards/nxp/mr_canhubk3/mr_canhubk3.dts:119 */

			/* node '/pinctrl/qdec_s32/group1' defined in zephyr/boards/nxp/mr_canhubk3/mr_canhubk3-pinctrl.dtsi:333 */
			group1 {
				pinmux = < 0x22ad88 >,
				         < 0x23ad08 >,
				         < 0x111b18 >,
				         < 0x871ba0 >; /* in zephyr/boards/nxp/mr_canhubk3/mr_canhubk3-pinctrl.dtsi:334 */
				input-enable;          /* in zephyr/boards/nxp/mr_canhubk3/mr_canhubk3-pinctrl.dtsi:338 */
			};
		};
	};

	/* node '/leds' defined in zephyr/boards/nxp/mr_canhubk3/mr_canhubk3.dts:51 */
	leds {
		compatible = "gpio-leds"; /* in zephyr/boards/nxp/mr_canhubk3/mr_canhubk3.dts:52 */

		/* node '/leds/user_led1_green' defined in zephyr/boards/nxp/mr_canhubk3/mr_canhubk3.dts:54 */
		user_led1_green: user_led1_green {
			gpios = < &gpioa_h 0xb 0x1 >;  /* in zephyr/boards/nxp/mr_canhubk3/mr_canhubk3.dts:55 */
			label = "User RGB LED1 GREEN"; /* in zephyr/boards/nxp/mr_canhubk3/mr_canhubk3.dts:56 */
		};

		/* node '/leds/user_led1_blue' defined in zephyr/boards/nxp/mr_canhubk3/mr_canhubk3.dts:59 */
		user_led1_blue: user_led1_blue {
			gpios = < &gpioe_l 0xc 0x1 >; /* in zephyr/boards/nxp/mr_canhubk3/mr_canhubk3.dts:60 */
			label = "User RGB LED1 BLUE"; /* in zephyr/boards/nxp/mr_canhubk3/mr_canhubk3.dts:61 */
		};

		/* node '/leds/user_led1_red' defined in zephyr/boards/nxp/mr_canhubk3/mr_canhubk3.dts:64 */
		user_led1_red: user_led1_red {
			gpios = < &gpioe_l 0xe 0x1 >; /* in zephyr/boards/nxp/mr_canhubk3/mr_canhubk3.dts:65 */
			label = "User RGB LED1 RED";  /* in zephyr/boards/nxp/mr_canhubk3/mr_canhubk3.dts:66 */
		};

		/* node '/leds/can_led0' defined in zephyr/boards/nxp/mr_canhubk3/mr_canhubk3.dts:69 */
		can_led0: can_led0 {
			gpios = < &gpioc_h 0x2 0x1 >; /* in zephyr/boards/nxp/mr_canhubk3/mr_canhubk3.dts:70 */
			label = "CAN LED0";           /* in zephyr/boards/nxp/mr_canhubk3/mr_canhubk3.dts:71 */
		};

		/* node '/leds/can_led1' defined in zephyr/boards/nxp/mr_canhubk3/mr_canhubk3.dts:74 */
		can_led1: can_led1 {
			gpios = < &gpioe_l 0x5 0x1 >; /* in zephyr/boards/nxp/mr_canhubk3/mr_canhubk3.dts:75 */
			label = "CAN LED1";           /* in zephyr/boards/nxp/mr_canhubk3/mr_canhubk3.dts:76 */
		};

		/* node '/leds/can_led2' defined in zephyr/boards/nxp/mr_canhubk3/mr_canhubk3.dts:79 */
		can_led2: can_led2 {
			gpios = < &gpiod_h 0x4 0x1 >; /* in zephyr/boards/nxp/mr_canhubk3/mr_canhubk3.dts:80 */
			label = "CAN LED2";           /* in zephyr/boards/nxp/mr_canhubk3/mr_canhubk3.dts:81 */
		};

		/* node '/leds/can_led3' defined in zephyr/boards/nxp/mr_canhubk3/mr_canhubk3.dts:84 */
		can_led3: can_led3 {
			gpios = < &gpiob_h 0x8 0x1 >; /* in zephyr/boards/nxp/mr_canhubk3/mr_canhubk3.dts:85 */
			label = "CAN LED3";           /* in zephyr/boards/nxp/mr_canhubk3/mr_canhubk3.dts:86 */
		};

		/* node '/leds/can_led4' defined in zephyr/boards/nxp/mr_canhubk3/mr_canhubk3.dts:89 */
		can_led4: can_led4 {
			gpios = < &gpiob_h 0xa 0x1 >; /* in zephyr/boards/nxp/mr_canhubk3/mr_canhubk3.dts:90 */
			label = "CAN LED4";           /* in zephyr/boards/nxp/mr_canhubk3/mr_canhubk3.dts:91 */
		};

		/* node '/leds/can_led5' defined in zephyr/boards/nxp/mr_canhubk3/mr_canhubk3.dts:94 */
		can_led5: can_led5 {
			gpios = < &gpiod_h 0xf 0x1 >; /* in zephyr/boards/nxp/mr_canhubk3/mr_canhubk3.dts:95 */
			label = "CAN LED5";           /* in zephyr/boards/nxp/mr_canhubk3/mr_canhubk3.dts:96 */
		};
	};

	/* node '/pwmleds' defined in zephyr/boards/nxp/mr_canhubk3/mr_canhubk3.dts:101 */
	pwmleds {
		compatible = "pwm-leds"; /* in zephyr/boards/nxp/mr_canhubk3/mr_canhubk3.dts:102 */

		/* node '/pwmleds/user_led1_blue' defined in zephyr/boards/nxp/mr_canhubk3/mr_canhubk3.dts:104 */
		user_led1_blue_pwm: user_led1_blue {
			pwms = < &emios1_pwm 0x5 0x1312d00 0x1 >; /* in zephyr/boards/nxp/mr_canhubk3/mr_canhubk3.dts:105 */
		};

		/* node '/pwmleds/user_led1_green' defined in zephyr/boards/nxp/mr_canhubk3/mr_canhubk3.dts:108 */
		user_led1_green_pwm: user_led1_green {
			pwms = < &emios1_pwm 0xa 0x1312d00 0x1 >; /* in zephyr/boards/nxp/mr_canhubk3/mr_canhubk3.dts:109 */
		};

		/* node '/pwmleds/user_led1_red' defined in zephyr/boards/nxp/mr_canhubk3/mr_canhubk3.dts:112 */
		user_led1_red_pwm: user_led1_red {
			pwms = < &emios0_pwm 0x13 0x1312d00 0x1 >; /* in zephyr/boards/nxp/mr_canhubk3/mr_canhubk3.dts:113 */
		};
	};

	/* node '/qdec0' defined in zephyr/boards/nxp/mr_canhubk3/mr_canhubk3.dts:117 */
	qdec0: qdec0 {
		compatible = "nxp,qdec-s32";                /* in zephyr/boards/nxp/mr_canhubk3/mr_canhubk3.dts:118 */
		pinctrl-0 = < &qdec_s32 >;                  /* in zephyr/boards/nxp/mr_canhubk3/mr_canhubk3.dts:119 */
		pinctrl-names = "default";                  /* in zephyr/boards/nxp/mr_canhubk3/mr_canhubk3.dts:120 */
		micro-ticks-per-rev = < 0x28dafc00 >;       /* in zephyr/boards/nxp/mr_canhubk3/mr_canhubk3.dts:121 */
		status = "okay";                            /* in zephyr/boards/nxp/mr_canhubk3/mr_canhubk3.dts:122 */
		trgmux = < &trgmux >;                       /* in zephyr/boards/nxp/mr_canhubk3/mr_canhubk3.dts:123 */
		trgmux-io-config = < 0x0 0x25 0x6b >,
		                   < 0x1 0x26 0x6c >,
		                   < 0x2 0x90 0x3e >,
		                   < 0x3 0x91 0x3f >;       /* in zephyr/boards/nxp/mr_canhubk3/mr_canhubk3.dts:124 */
		lcu = < &lcu1 >;                            /* in zephyr/boards/nxp/mr_canhubk3/mr_canhubk3.dts:130 */
		lcu-input-idx = < 0x0 0x1 0x2 0x3 >;        /* in zephyr/boards/nxp/mr_canhubk3/mr_canhubk3.dts:131 */
		lcu-mux-sel = < 0x1 0x2 0xd 0xe >;          /* in zephyr/boards/nxp/mr_canhubk3/mr_canhubk3.dts:133 */
		lcu-output-filter-config = < 0x0 0x5 0x5 >,
		                           < 0x1 0x5 0x5 >,
		                           < 0x2 0x2 0x2 >,
		                           < 0x3 0x2 0x2 >; /* in zephyr/boards/nxp/mr_canhubk3/mr_canhubk3.dts:135 */
		emios = < &emios0 >;                        /* in zephyr/boards/nxp/mr_canhubk3/mr_canhubk3.dts:141 */
		emios-channels = < 0x6 0x7 >;               /* in zephyr/boards/nxp/mr_canhubk3/mr_canhubk3.dts:146 */
	};

	/* node '/gpio_keys' defined in zephyr/boards/nxp/mr_canhubk3/mr_canhubk3.dts:149 */
	gpio_keys {
		compatible = "gpio-keys"; /* in zephyr/boards/nxp/mr_canhubk3/mr_canhubk3.dts:150 */

		/* node '/gpio_keys/button_0' defined in zephyr/boards/nxp/mr_canhubk3/mr_canhubk3.dts:152 */
		user_button_1: button_0 {
			label = "User SW1";           /* in zephyr/boards/nxp/mr_canhubk3/mr_canhubk3.dts:153 */
			gpios = < &gpiod_l 0xf 0x0 >; /* in zephyr/boards/nxp/mr_canhubk3/mr_canhubk3.dts:154 */
			zephyr,code = < 0xb >;        /* in zephyr/boards/nxp/mr_canhubk3/mr_canhubk3.dts:155 */
		};

		/* node '/gpio_keys/button_1' defined in zephyr/boards/nxp/mr_canhubk3/mr_canhubk3.dts:158 */
		user_button_2: button_1 {
			label = "User SW2";           /* in zephyr/boards/nxp/mr_canhubk3/mr_canhubk3.dts:159 */
			gpios = < &gpioa_h 0x9 0x0 >; /* in zephyr/boards/nxp/mr_canhubk3/mr_canhubk3.dts:160 */
			zephyr,code = < 0x2 >;        /* in zephyr/boards/nxp/mr_canhubk3/mr_canhubk3.dts:161 */
		};
	};

	/* node '/can-phy0' defined in zephyr/boards/nxp/mr_canhubk3/mr_canhubk3.dts:165 */
	can_phy0: can-phy0 {
		compatible = "nxp,tja1443",
		             "can-transceiver-gpio";  /* in zephyr/boards/nxp/mr_canhubk3/mr_canhubk3.dts:166 */
		enable-gpios = < &gpioc_h 0x8 0x0 >;  /* in zephyr/boards/nxp/mr_canhubk3/mr_canhubk3.dts:167 */
		standby-gpios = < &gpioc_h 0x5 0x1 >; /* in zephyr/boards/nxp/mr_canhubk3/mr_canhubk3.dts:168 */
		max-bitrate = < 0x4c4b40 >;           /* in zephyr/boards/nxp/mr_canhubk3/mr_canhubk3.dts:169 */
		#phy-cells = < 0x0 >;                 /* in zephyr/boards/nxp/mr_canhubk3/mr_canhubk3.dts:170 */
		phandle = < 0x10 >;                   /* in zephyr/boards/nxp/mr_canhubk3/mr_canhubk3.dts:377 */
	};

	/* node '/can-phy1' defined in zephyr/boards/nxp/mr_canhubk3/mr_canhubk3.dts:173 */
	can_phy1: can-phy1 {
		compatible = "nxp,tja1443",
		             "can-transceiver-gpio";  /* in zephyr/boards/nxp/mr_canhubk3/mr_canhubk3.dts:174 */
		enable-gpios = < &gpiod_l 0x2 0x0 >;  /* in zephyr/boards/nxp/mr_canhubk3/mr_canhubk3.dts:175 */
		standby-gpios = < &gpiod_h 0x7 0x1 >; /* in zephyr/boards/nxp/mr_canhubk3/mr_canhubk3.dts:176 */
		max-bitrate = < 0x4c4b40 >;           /* in zephyr/boards/nxp/mr_canhubk3/mr_canhubk3.dts:177 */
		#phy-cells = < 0x0 >;                 /* in zephyr/boards/nxp/mr_canhubk3/mr_canhubk3.dts:178 */
		phandle = < 0x12 >;                   /* in zephyr/boards/nxp/mr_canhubk3/mr_canhubk3.dts:384 */
	};

	/* node '/can-phy2' defined in zephyr/boards/nxp/mr_canhubk3/mr_canhubk3.dts:181 */
	can_phy2: can-phy2 {
		compatible = "nxp,tja1463",
		             "can-transceiver-gpio";  /* in zephyr/boards/nxp/mr_canhubk3/mr_canhubk3.dts:182 */
		enable-gpios = < &gpiod_l 0x4 0x0 >;  /* in zephyr/boards/nxp/mr_canhubk3/mr_canhubk3.dts:183 */
		standby-gpios = < &gpiod_h 0x6 0x1 >; /* in zephyr/boards/nxp/mr_canhubk3/mr_canhubk3.dts:184 */
		max-bitrate = < 0x7a1200 >;           /* in zephyr/boards/nxp/mr_canhubk3/mr_canhubk3.dts:185 */
		#phy-cells = < 0x0 >;                 /* in zephyr/boards/nxp/mr_canhubk3/mr_canhubk3.dts:186 */
		phandle = < 0x14 >;                   /* in zephyr/boards/nxp/mr_canhubk3/mr_canhubk3.dts:390 */
	};

	/* node '/can-phy3' defined in zephyr/boards/nxp/mr_canhubk3/mr_canhubk3.dts:189 */
	can_phy3: can-phy3 {
		compatible = "nxp,tja1463",
		             "can-transceiver-gpio";  /* in zephyr/boards/nxp/mr_canhubk3/mr_canhubk3.dts:190 */
		enable-gpios = < &gpiob_l 0x0 0x0 >;  /* in zephyr/boards/nxp/mr_canhubk3/mr_canhubk3.dts:191 */
		standby-gpios = < &gpiob_l 0x1 0x1 >; /* in zephyr/boards/nxp/mr_canhubk3/mr_canhubk3.dts:192 */
		max-bitrate = < 0x7a1200 >;           /* in zephyr/boards/nxp/mr_canhubk3/mr_canhubk3.dts:193 */
		#phy-cells = < 0x0 >;                 /* in zephyr/boards/nxp/mr_canhubk3/mr_canhubk3.dts:194 */
		phandle = < 0x16 >;                   /* in zephyr/boards/nxp/mr_canhubk3/mr_canhubk3.dts:396 */
	};

	/* node '/can-phy4' defined in zephyr/boards/nxp/mr_canhubk3/mr_canhubk3.dts:197 */
	can_phy4: can-phy4 {
		compatible = "nxp,tja1153",
		             "can-transceiver-gpio";  /* in zephyr/boards/nxp/mr_canhubk3/mr_canhubk3.dts:198 */
		enable-gpios = < &gpioc_h 0xa 0x0 >;  /* in zephyr/boards/nxp/mr_canhubk3/mr_canhubk3.dts:199 */
		standby-gpios = < &gpioc_h 0x9 0x1 >; /* in zephyr/boards/nxp/mr_canhubk3/mr_canhubk3.dts:200 */
		max-bitrate = < 0x1e8480 >;           /* in zephyr/boards/nxp/mr_canhubk3/mr_canhubk3.dts:201 */
		#phy-cells = < 0x0 >;                 /* in zephyr/boards/nxp/mr_canhubk3/mr_canhubk3.dts:202 */
		phandle = < 0x18 >;                   /* in zephyr/boards/nxp/mr_canhubk3/mr_canhubk3.dts:402 */
	};

	/* node '/can-phy5' defined in zephyr/boards/nxp/mr_canhubk3/mr_canhubk3.dts:205 */
	can_phy5: can-phy5 {
		compatible = "nxp,tja1153",
		             "can-transceiver-gpio";  /* in zephyr/boards/nxp/mr_canhubk3/mr_canhubk3.dts:206 */
		enable-gpios = < &gpioe_h 0x1 0x0 >;  /* in zephyr/boards/nxp/mr_canhubk3/mr_canhubk3.dts:207 */
		standby-gpios = < &gpiod_h 0xe 0x1 >; /* in zephyr/boards/nxp/mr_canhubk3/mr_canhubk3.dts:208 */
		max-bitrate = < 0x1e8480 >;           /* in zephyr/boards/nxp/mr_canhubk3/mr_canhubk3.dts:209 */
		#phy-cells = < 0x0 >;                 /* in zephyr/boards/nxp/mr_canhubk3/mr_canhubk3.dts:210 */
		phandle = < 0x1a >;                   /* in zephyr/boards/nxp/mr_canhubk3/mr_canhubk3.dts:408 */
	};
};
